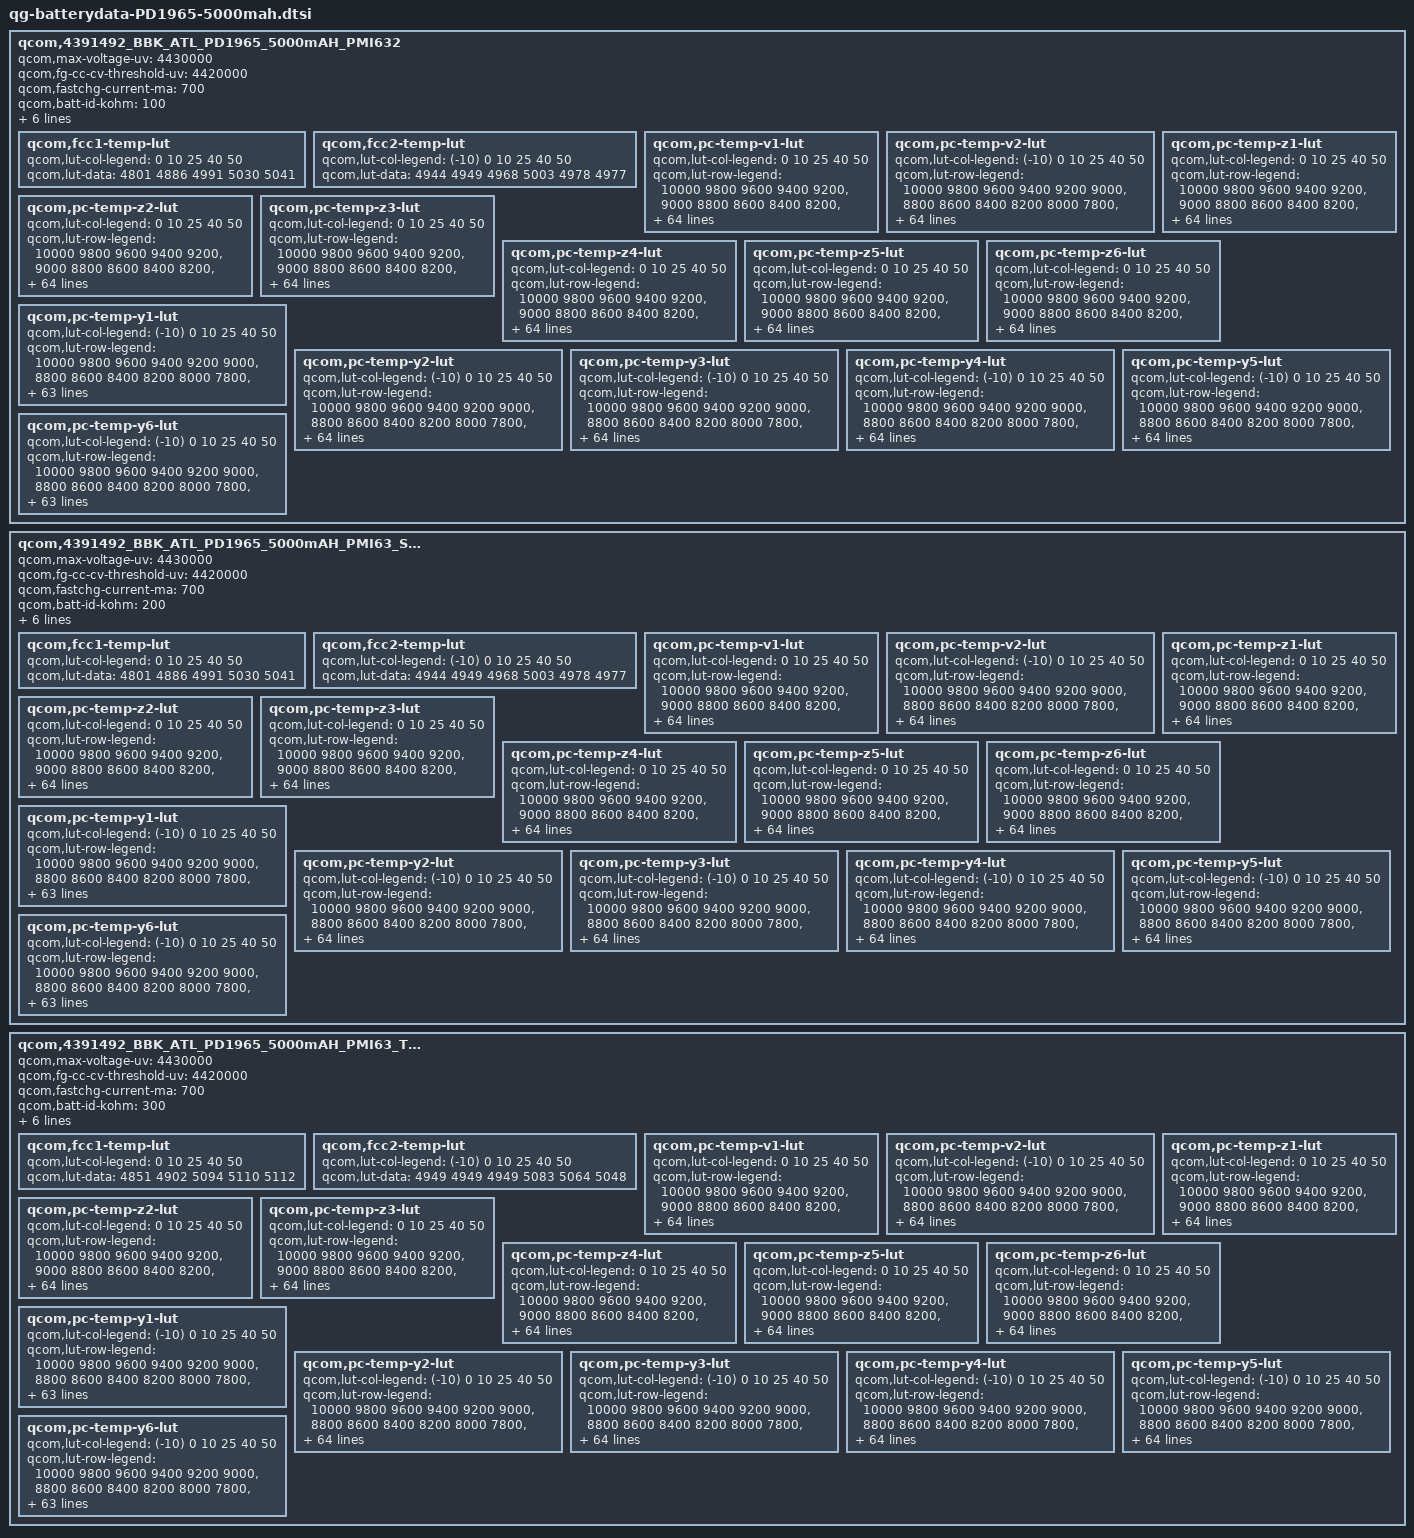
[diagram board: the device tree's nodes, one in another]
qcom,4391492_BBK_ATL_PD1965_5000mAH_PMI632 {
    /* 4391492_BBK_ATL_PD1965_5000mAH_PMI632_averaged_MasterSlave_Jan2th2020 */
    qcom,max-voltage-uv = <4430000>;
    qcom,fg-cc-cv-threshold-uv = <4420000>;
    qcom,fastchg-current-ma = <700>;
    qcom,batt-id-kohm = <100>;
    qcom,nom-batt-capacity-mah = <4880>;/*min value*/
    qcom,battery-beta = <3440>;
    qcom,battery-therm-kohm = <10>;
    qcom,battery-type = "4391492_BBK_ATL_PD1965_5000mAH_PMI632_averaged_MasterSlave_Jan2th2020";
    qcom,qg-batt-profile-ver = <100>;

	qcom,fcc1-temp-lut {
		qcom,lut-col-legend = <0 10 25 40 50>;
		qcom,lut-data = <4801 4886 4991 5030 5041>;
	};

	qcom,fcc2-temp-lut {
		qcom,lut-col-legend = <(-10) 0 10 25 40 50>;
		qcom,lut-data = <4944 4949 4968 5003 4978 4977>;
	};

	qcom,pc-temp-v1-lut {
		qcom,lut-col-legend = <0 10 25 40 50>;
		qcom,lut-row-legend = <10000 9800 9600 9400 9200>,
			<9000 8800 8600 8400 8200>,
			<8000 7800 7600 7400 7200>,
			<7000 6800 6600 6400 6200>,
			<6000 5800 5600 5400 5200>,
			<5000 4800 4600 4400 4200>,
			<4000 3800 3600 3400 3200>,
			<3000 2800 2600 2400 2200>,
			<2000 1800 1600 1400 1200>,
			<1000 900 800 700 600>,
			<500 400 300 200 100>,
			<0>;
		qcom,lut-data = <44061 44137 44195 44220 44225>,
			<43896 43960 44010 44027 44033>,
			<43679 43763 43816 43839 43847>,
			<43447 43549 43614 43642 43653>,
			<43217 43327 43400 43431 43447>,
			<42980 43094 43178 43212 43231>,
			<42744 42856 42942 42983 43006>,
			<42505 42617 42700 42747 42770>,
			<42269 42378 42459 42508 42533>,
			<42038 42140 42218 42266 42293>,
			<41811 41906 41979 42024 42052>,
			<41590 41675 41742 41787 41815>,
			<41372 41451 41509 41553 41581>,
			<41161 41235 41284 41323 41352>,
			<40958 41023 41065 41099 41129>,
			<40764 40817 40854 40882 40912>,
			<40574 40617 40648 40674 40702>,
			<40386 40427 40449 40474 40498>,
			<40200 40257 40265 40284 40304>,
			<40005 40080 40095 40109 40126>,
			<39791 39852 39909 39929 39945>,
			<39579 39578 39667 39704 39726>,
			<39384 39352 39415 39455 39481>,
			<39195 39187 39218 39246 39272>,
			<39039 39048 39057 39074 39097>,
			<38925 38925 38916 38924 38944>,
			<38829 38816 38792 38797 38811>,
			<38742 38719 38683 38686 38693>,
			<38661 38630 38584 38583 38584>,
			<38589 38549 38493 38484 38482>,
			<38526 38479 38412 38394 38388>,
			<38470 38415 38337 38310 38301>,
			<38419 38359 38270 38234 38221>,
			<38373 38308 38213 38167 38149>,
			<38330 38263 38167 38111 38086>,
			<38293 38219 38120 38055 38021>,
			<38260 38182 38072 37992 37944>,
			<38217 38138 38020 37924 37857>,
			<38138 38063 37948 37845 37767>,
			<38027 37952 37847 37750 37671>,
			<37903 37828 37733 37642 37564>,
			<37758 37687 37608 37516 37436>,
			<37610 37532 37467 37374 37293>,
			<37462 37353 37295 37212 37130>,
			<37305 37212 37154 37083 37014>,
			<37205 37125 37081 37014 36951>,
			<37170 37099 37059 36995 36933>,
			<37142 37079 37039 36982 36918>,
			<37109 37057 37014 36958 36891>,
			<37015 36951 36890 36798 36701>,
			<36674 36585 36528 36432 36331>,
			<36193 36111 36051 35952 35852>,
			<35580 35489 35438 35337 35235>,
			<34742 34642 34603 34498 34396>,
			<33413 33295 33303 33195 33092>,
			<30000 30000 30000 30000 30000>;
	};

	qcom,pc-temp-v2-lut {
		qcom,lut-col-legend = <(-10) 0 10 25 40 50>;
		qcom,lut-row-legend = <10000 9800 9600 9400 9200 9000>,
			<8800 8600 8400 8200 8000 7800>,
			<7600 7400 7200 7000 6800 6600>,
			<6400 6200 6000 5800 5600 5400>,
			<5200 5000 4800 4600 4400 4200>,
			<4000 3800 3600 3400 3200 3000>,
			<2800 2600 2400 2200 2000 1800>,
			<1600 1400 1200 1000 900 800>,
			<700 600 500 400 300 200>,
			<100 0>;
		qcom,lut-data = <44225 44175 44175 44190 44110 44115>,
			<43838 43904 43937 43970 43898 43903>,
			<43495 43643 43705 43752 43685 43689>,
			<43207 43396 43481 43536 43470 43476>,
			<42966 43163 43266 43323 43256 43263>,
			<42730 42928 43047 43104 43035 43044>,
			<42478 42681 42813 42871 42803 42814>,
			<42215 42431 42573 42630 42565 42576>,
			<41919 42185 42335 42390 42326 42339>,
			<41550 41945 42097 42146 42085 42099>,
			<41263 41709 41862 41906 41848 41863>,
			<41143 41470 41628 41668 41613 41629>,
			<41062 41236 41399 41435 41383 41399>,
			<40902 41023 41175 41207 41158 41174>,
			<40518 40835 40957 40983 40937 40953>,
			<40121 40642 40744 40766 40724 40740>,
			<39889 40420 40539 40557 40519 40533>,
			<39705 40177 40335 40354 40321 40333>,
			<39488 39932 40121 40159 40130 40142>,
			<39212 39677 39893 39974 39951 39964>,
			<38947 39429 39659 39773 39758 39773>,
			<38733 39198 39415 39519 39511 39528>,
			<38548 38981 39170 39253 39243 39263>,
			<38415 38794 38971 39051 39041 39061>,
			<38323 38635 38812 38889 38888 38907>,
			<38250 38492 38673 38749 38755 38774>,
			<38189 38356 38545 38623 38632 38650>,
			<38138 38228 38430 38511 38522 38538>,
			<38087 38129 38323 38406 38419 38434>,
			<38037 38055 38221 38307 38323 38335>,
			<37986 37993 38127 38217 38234 38245>,
			<37935 37940 38042 38134 38156 38163>,
			<37882 37893 37963 38057 38083 38086>,
			<37825 37845 37895 37982 38007 38003>,
			<37764 37798 37839 37910 37929 37914>,
			<37698 37748 37785 37835 37844 37817>,
			<37628 37688 37731 37753 37743 37703>,
			<37553 37620 37677 37667 37630 37578>,
			<37471 37539 37610 37583 37529 37469>,
			<37379 37442 37523 37501 37442 37380>,
			<37278 37330 37417 37409 37350 37287>,
			<37163 37201 37291 37295 37233 37167>,
			<37030 37051 37143 37164 37100 37031>,
			<36905 36898 36987 36993 36951 36888>,
			<36790 36757 36865 36914 36871 36810>,
			<36703 36665 36807 36886 36848 36787>,
			<36663 36626 36777 36869 36829 36768>,
			<36619 36577 36729 36840 36800 36740>,
			<36552 36490 36653 36783 36728 36646>,
			<36437 36316 36465 36614 36486 36366>,
			<36149 35975 36069 36201 36045 35916>,
			<35648 35477 35504 35666 35485 35348>,
			<34957 34800 34782 34970 34754 34598>,
			<33964 33826 33786 34010 33704 33557>,
			<32369 32283 32339 32559 32419 32087>,
			<29589 29119 29003 29070 29002 29003>;
	};

	qcom,pc-temp-z1-lut {
		qcom,lut-col-legend = <0 10 25 40 50>;
		qcom,lut-row-legend = <10000 9800 9600 9400 9200>,
			<9000 8800 8600 8400 8200>,
			<8000 7800 7600 7400 7200>,
			<7000 6800 6600 6400 6200>,
			<6000 5800 5600 5400 5200>,
			<5000 4800 4600 4400 4200>,
			<4000 3800 3600 3400 3200>,
			<3000 2800 2600 2400 2200>,
			<2000 1800 1600 1400 1200>,
			<1000 900 800 700 600>,
			<500 400 300 200 100>,
			<0>;
		qcom,lut-data = <12152 11640 11121 10911 10832>,
			<12122 11562 11036 10812 10751>,
			<12087 11520 10979 10773 10727>,
			<12059 11491 10965 10762 10720>,
			<12039 11480 10958 10759 10719>,
			<12017 11483 10953 10757 10717>,
			<12010 11488 10948 10753 10715>,
			<12010 11487 10944 10750 10713>,
			<12010 11472 10939 10747 10711>,
			<12009 11459 10934 10744 10710>,
			<12003 11460 10930 10742 10710>,
			<12000 11463 10926 10741 10709>,
			<12001 11463 10924 10741 10709>,
			<12001 11459 10923 10741 10709>,
			<12001 11455 10924 10742 10708>,
			<11996 11455 10925 10742 10707>,
			<11991 11456 10923 10741 10708>,
			<11991 11456 10921 10740 10710>,
			<11991 11450 10922 10739 10712>,
			<11993 11445 10926 10741 10712>,
			<12001 11449 10929 10742 10713>,
			<12010 11463 10931 10743 10713>,
			<12011 11469 10933 10744 10715>,
			<12003 11465 10936 10745 10716>,
			<12000 11460 10940 10748 10717>,
			<12013 11460 10944 10750 10718>,
			<12030 11463 10946 10753 10720>,
			<12033 11467 10948 10756 10723>,
			<12027 11469 10952 10759 10725>,
			<12022 11472 10958 10761 10727>,
			<12029 11473 10963 10764 10729>,
			<12046 11474 10966 10767 10732>,
			<12053 11475 10968 10771 10734>,
			<12042 11474 10971 10773 10737>,
			<12029 11474 10977 10775 10739>,
			<12030 11475 10982 10777 10741>,
			<12042 11483 10988 10781 10743>,
			<12051 11491 10994 10786 10746>,
			<12052 11495 10997 10788 10747>,
			<12052 11497 10999 10789 10749>,
			<12056 11500 11001 10789 10751>,
			<12074 11501 11002 10790 10753>,
			<12080 11504 11003 10792 10755>,
			<12076 11507 11005 10793 10755>,
			<12070 11519 11008 10794 10755>,
			<12063 11504 11011 10796 10753>,
			<12067 11500 11014 10797 10757>,
			<12065 11501 11016 10801 10755>,
			<12079 11501 11017 10801 10758>,
			<12078 11508 11019 10805 10761>,
			<12084 11524 11024 10808 10762>,
			<12106 11534 11030 10810 10766>,
			<12112 11537 11039 10818 10771>,
			<12156 11578 11050 10824 10776>,
			<12156 11578 11050 10824 10776>,
			<12156 11578 11050 10824 10776>;
	};

	qcom,pc-temp-z2-lut {
		qcom,lut-col-legend = <0 10 25 40 50>;
		qcom,lut-row-legend = <10000 9800 9600 9400 9200>,
			<9000 8800 8600 8400 8200>,
			<8000 7800 7600 7400 7200>,
			<7000 6800 6600 6400 6200>,
			<6000 5800 5600 5400 5200>,
			<5000 4800 4600 4400 4200>,
			<4000 3800 3600 3400 3200>,
			<3000 2800 2600 2400 2200>,
			<2000 1800 1600 1400 1200>,
			<1000 900 800 700 600>,
			<500 400 300 200 100>,
			<0>;
		qcom,lut-data = <11316 10650 11293 11777 11181>,
			<10578 10735 11148 11036 11105>,
			<10543 10721 11049 11125 11113>,
			<10542 10695 11020 11162 11126>,
			<10542 10684 11008 11157 11158>,
			<10543 10694 11002 11146 11195>,
			<10545 10711 11012 11109 11207>,
			<10553 10717 11029 11034 11203>,
			<10562 10720 11032 11011 11204>,
			<10565 10722 11036 11112 11229>,
			<10566 10728 11035 11212 11256>,
			<10567 10735 11027 11179 11246>,
			<10573 10737 11020 11081 11206>,
			<10581 10736 11024 11047 11189>,
			<10581 10736 11045 11071 11218>,
			<10572 10731 11057 11103 11253>,
			<10563 10718 11043 11128 11264>,
			<10559 10709 11023 11150 11275>,
			<10557 10703 11019 11154 11270>,
			<10550 10699 11018 11134 11245>,
			<10497 10695 11018 11116 11211>,
			<10441 10683 11015 11114 11168>,
			<10442 10671 11008 11109 11109>,
			<10467 10650 10996 11103 11075>,
			<10482 10630 10965 11092 11057>,
			<10474 10626 10948 11080 11047>,
			<10461 10627 10952 11065 11054>,
			<10458 10628 10958 11044 11077>,
			<10463 10636 10958 11039 11104>,
			<10470 10648 10950 11039 11142>,
			<10479 10654 10945 11050 11180>,
			<10491 10656 10974 11088 11218>,
			<10498 10658 11022 11137 11270>,
			<10501 10661 11049 11160 11306>,
			<10504 10664 11067 11139 11328>,
			<10509 10665 11082 11135 11353>,
			<10517 10669 11099 11220 11445>,
			<10526 10676 11121 11347 11583>,
			<10547 10704 11159 11404 11619>,
			<10572 10759 11234 11409 11570>,
			<10576 10779 11276 11397 11529>,
			<10560 10770 11237 11349 11467>,
			<10579 10766 11198 11296 11390>,
			<10784 10792 11224 11289 11356>,
			<11474 10833 11233 11304 11382>,
			<11833 10789 11240 11296 11320>,
			<11508 10793 11214 11209 11379>,
			<11152 10830 11172 11304 11450>,
			<11789 11061 11135 11310 11483>,
			<10999 10982 11277 11206 11127>,
			<10491 10912 11162 11075 11000>,
			<10250 10799 11088 10969 10908>,
			<9946 10805 11051 10910 10902>,
			<9604 10533 10977 10881 10801>,
			<9604 10533 10977 10881 10801>,
			<9604 10533 10977 10881 10801>;
	};

	qcom,pc-temp-z3-lut {
		qcom,lut-col-legend = <0 10 25 40 50>;
		qcom,lut-row-legend = <10000 9800 9600 9400 9200>,
			<9000 8800 8600 8400 8200>,
			<8000 7800 7600 7400 7200>,
			<7000 6800 6600 6400 6200>,
			<6000 5800 5600 5400 5200>,
			<5000 4800 4600 4400 4200>,
			<4000 3800 3600 3400 3200>,
			<3000 2800 2600 2400 2200>,
			<2000 1800 1600 1400 1200>,
			<1000 900 800 700 600>,
			<500 400 300 200 100>,
			<0>;
		qcom,lut-data = <19258 19323 19328 19307 19299>,
			<19291 19439 19376 19327 19315>,
			<19488 19498 19406 19338 19319>,
			<19653 19537 19408 19343 19320>,
			<19674 19552 19402 19343 19320>,
			<19685 19547 19398 19343 19320>,
			<19687 19538 19396 19340 19320>,
			<19679 19529 19394 19332 19319>,
			<19667 19519 19390 19328 19318>,
			<19659 19513 19379 19327 19318>,
			<19652 19513 19374 19327 19319>,
			<19647 19513 19375 19327 19318>,
			<19641 19512 19376 19327 19317>,
			<19636 19503 19373 19327 19315>,
			<19635 19496 19359 19325 19311>,
			<19639 19499 19351 19322 19307>,
			<19642 19507 19353 19319 19306>,
			<19642 19510 19355 19314 19305>,
			<19642 19502 19355 19312 19304>,
			<19643 19495 19356 19312 19302>,
			<19660 19500 19358 19314 19301>,
			<19680 19521 19376 19324 19306>,
			<19687 19537 19399 19345 19321>,
			<19692 19547 19404 19353 19327>,
			<19695 19553 19404 19354 19328>,
			<19697 19552 19404 19355 19329>,
			<19699 19547 19405 19349 19328>,
			<19698 19542 19405 19336 19326>,
			<19691 19537 19403 19331 19325>,
			<19682 19533 19395 19330 19325>,
			<19674 19527 19389 19330 19324>,
			<19666 19521 19388 19330 19323>,
			<19661 19515 19387 19331 19320>,
			<19657 19511 19385 19331 19317>,
			<19654 19508 19379 19329 19314>,
			<19652 19506 19376 19326 19312>,
			<19649 19506 19377 19325 19312>,
			<19646 19506 19379 19324 19313>,
			<19638 19500 19379 19324 19314>,
			<19628 19489 19375 19322 19314>,
			<19624 19484 19371 19322 19315>,
			<19624 19487 19367 19325 19315>,
			<19582 19488 19364 19328 19317>,
			<19282 19476 19365 19327 19321>,
			<19259 19451 19364 19324 19315>,
			<19258 19450 19348 19320 19307>,
			<19258 19447 19349 19321 19305>,
			<19258 19433 19351 19313 19303>,
			<19258 19348 19347 19306 19300>,
			<19258 19379 19344 19323 19318>,
			<19259 19408 19356 19327 19321>,
			<19260 19288 19358 19332 19322>,
			<19262 19314 19352 19329 19326>,
			<19266 19311 19341 19334 19328>,
			<19266 19311 19341 19334 19328>,
			<19266 19311 19341 19334 19328>;
	};

	qcom,pc-temp-z4-lut {
		qcom,lut-col-legend = <0 10 25 40 50>;
		qcom,lut-row-legend = <10000 9800 9600 9400 9200>,
			<9000 8800 8600 8400 8200>,
			<8000 7800 7600 7400 7200>,
			<7000 6800 6600 6400 6200>,
			<6000 5800 5600 5400 5200>,
			<5000 4800 4600 4400 4200>,
			<4000 3800 3600 3400 3200>,
			<3000 2800 2600 2400 2200>,
			<2000 1800 1600 1400 1200>,
			<1000 900 800 700 600>,
			<500 400 300 200 100>,
			<0>;
		qcom,lut-data = <15453 15196 14961 14781 14759>,
			<15468 15215 14956 14833 14781>,
			<15391 15195 14945 14808 14764>,
			<15294 15105 14926 14791 14751>,
			<15193 15027 14887 14782 14745>,
			<15085 14988 14856 14775 14741>,
			<15031 14958 14841 14769 14736>,
			<15011 14939 14830 14765 14732>,
			<14997 14927 14821 14760 14727>,
			<14983 14916 14814 14753 14721>,
			<14969 14901 14806 14746 14715>,
			<14960 14885 14794 14739 14711>,
			<14954 14876 14782 14732 14707>,
			<14949 14869 14777 14726 14703>,
			<14948 14866 14775 14720 14699>,
			<14948 14869 14773 14715 14695>,
			<14948 14875 14766 14709 14690>,
			<14950 14877 14758 14704 14683>,
			<14958 14866 14754 14700 14679>,
			<14972 14853 14751 14696 14677>,
			<15025 14904 14751 14694 14676>,
			<15087 15063 14804 14714 14689>,
			<15120 15140 14881 14759 14723>,
			<15154 15092 14891 14773 14737>,
			<15170 15021 14876 14772 14738>,
			<15131 14984 14859 14771 14738>,
			<15065 14960 14842 14768 14736>,
			<15036 14945 14826 14765 14730>,
			<15023 14935 14817 14760 14724>,
			<15016 14928 14810 14751 14717>,
			<15014 14924 14805 14742 14710>,
			<15012 14922 14800 14733 14705>,
			<15011 14921 14796 14726 14700>,
			<15010 14919 14792 14722 14696>,
			<15009 14918 14788 14719 14693>,
			<15005 14916 14786 14718 14691>,
			<14996 14911 14793 14728 14697>,
			<14987 14905 14805 14747 14711>,
			<14980 14900 14807 14751 14714>,
			<14973 14895 14807 14745 14710>,
			<14961 14887 14806 14737 14705>,
			<14939 14869 14793 14729 14701>,
			<14965 14855 14780 14723 14698>,
			<15203 14850 14779 14726 14703>,
			<15177 14825 14771 14725 14703>,
			<15146 14784 14752 14714 14691>,
			<15137 14766 14729 14701 14679>,
			<15126 14763 14705 14683 14663>,
			<15115 14839 14695 14679 14658>,
			<15115 14813 14715 14682 14663>,
			<15136 14797 14705 14679 14662>,
			<15144 14920 14701 14674 14662>,
			<15151 14897 14707 14676 14659>,
			<15181 14909 14717 14673 14659>,
			<15181 14909 14717 14673 14659>,
			<15181 14909 14717 14673 14659>;
	};

	qcom,pc-temp-z5-lut {
		qcom,lut-col-legend = <0 10 25 40 50>;
		qcom,lut-row-legend = <10000 9800 9600 9400 9200>,
			<9000 8800 8600 8400 8200>,
			<8000 7800 7600 7400 7200>,
			<7000 6800 6600 6400 6200>,
			<6000 5800 5600 5400 5200>,
			<5000 4800 4600 4400 4200>,
			<4000 3800 3600 3400 3200>,
			<3000 2800 2600 2400 2200>,
			<2000 1800 1600 1400 1200>,
			<1000 900 800 700 600>,
			<500 400 300 200 100>,
			<0>;
		qcom,lut-data = <11158 12046 13940 14471 15125>,
			<11606 14259 16208 16833 17677>,
			<13986 16162 17732 17960 18263>,
			<16501 17974 18122 18545 18557>,
			<18058 18936 18261 18831 18767>,
			<19333 19189 18360 18990 18904>,
			<19700 19332 18472 18672 18957>,
			<19583 19284 18558 17741 18921>,
			<19428 18919 18408 17324 18920>,
			<19333 18663 17717 17467 19171>,
			<19240 18914 17321 17644 19460>,
			<19194 19378 17666 17759 19500>,
			<19112 19474 18146 18047 19457>,
			<19019 19128 17971 18160 19382>,
			<19144 18814 16869 18180 18826>,
			<19663 19161 16228 18178 18225>,
			<20061 20028 16501 17923 18195>,
			<19866 20331 16930 17359 18323>,
			<19399 19818 17206 17139 18396>,
			<19319 19222 17681 17429 18363>,
			<21137 19107 17901 17728 18248>,
			<23141 19215 17668 17686 17948>,
			<22748 19288 17346 17573 17457>,
			<20514 19219 17200 17602 17242>,
			<19211 19165 17184 17711 17187>,
			<19788 19411 17310 17778 17160>,
			<20863 20291 18077 17452 17313>,
			<21650 21201 19141 16765 17734>,
			<22341 22012 19567 16600 18102>,
			<22777 22724 19675 16978 19032>,
			<22859 22962 19910 17581 19849>,
			<22899 23042 20865 18552 20166>,
			<22938 23101 22060 19846 20721>,
			<22988 23156 22509 20636 21279>,
			<23029 23206 22547 21269 21955>,
			<23043 23303 22561 21610 22371>,
			<23030 23577 22883 21099 21798>,
			<23023 23798 23285 20129 20634>,
			<23024 23535 23227 19785 20348>,
			<23000 22858 22500 19417 20713>,
			<22928 22616 21665 19274 21070>,
			<22801 23027 20882 19855 21409>,
			<21309 23190 20236 20406 21801>,
			<12195 21264 19817 19776 22252>,
			<11411 19246 19595 18776 20258>,
			<11333 19812 18166 18422 18025>,
			<11317 19801 19192 19856 18766>,
			<11291 18707 21166 19869 20950>,
			<11233 13373 21303 19330 21183>,
			<11246 15041 17862 19535 22967>,
			<11268 15831 18956 19538 22898>,
			<11213 11840 18776 20570 22999>,
			<11137 12141 17447 19547 24357>,
			<11084 11961 16052 20015 23848>,
			<11084 11961 16052 20015 23848>,
			<11084 11961 16052 20015 23848>;
	};

	qcom,pc-temp-z6-lut {
		qcom,lut-col-legend = <0 10 25 40 50>;
		qcom,lut-row-legend = <10000 9800 9600 9400 9200>,
			<9000 8800 8600 8400 8200>,
			<8000 7800 7600 7400 7200>,
			<7000 6800 6600 6400 6200>,
			<6000 5800 5600 5400 5200>,
			<5000 4800 4600 4400 4200>,
			<4000 3800 3600 3400 3200>,
			<3000 2800 2600 2400 2200>,
			<2000 1800 1600 1400 1200>,
			<1000 900 800 700 600>,
			<500 400 300 200 100>,
			<0>;
		qcom,lut-data = <15443 14980 14630 14494 14470>,
			<15409 15014 14637 14510 14468>,
			<15404 15009 14636 14499 14459>,
			<15398 14969 14626 14491 14454>,
			<15357 14929 14604 14487 14452>,
			<15276 14901 14586 14483 14450>,
			<15224 14877 14577 14478 14447>,
			<15200 14858 14570 14472 14444>,
			<15181 14843 14562 14467 14441>,
			<15165 14830 14553 14463 14439>,
			<15150 14820 14545 14459 14436>,
			<15139 14811 14540 14456 14434>,
			<15129 14802 14536 14453 14431>,
			<15122 14792 14530 14450 14429>,
			<15120 14786 14523 14447 14425>,
			<15120 14788 14517 14443 14421>,
			<15120 14793 14514 14439 14418>,
			<15121 14794 14512 14434 14415>,
			<15125 14785 14512 14432 14413>,
			<15133 14776 14511 14431 14412>,
			<15165 14802 14512 14430 14410>,
			<15204 14885 14545 14444 14419>,
			<15228 14925 14592 14476 14443>,
			<15251 14910 14598 14487 14453>,
			<15262 14886 14593 14487 14454>,
			<15249 14872 14587 14487 14454>,
			<15227 14861 14581 14484 14453>,
			<15216 14854 14575 14476 14449>,
			<15211 14850 14570 14470 14446>,
			<15208 14846 14563 14466 14443>,
			<15206 14844 14559 14462 14440>,
			<15206 14841 14558 14460 14437>,
			<15206 14840 14557 14458 14434>,
			<15208 14840 14555 14456 14431>,
			<15210 14840 14552 14453 14428>,
			<15212 14841 14550 14452 14426>,
			<15215 14843 14555 14456 14430>,
			<15216 14845 14562 14465 14436>,
			<15217 14844 14564 14466 14438>,
			<15219 14841 14563 14463 14437>,
			<15220 14839 14561 14460 14435>,
			<15223 14838 14554 14459 14434>,
			<15221 14836 14548 14458 14434>,
			<15191 14834 14549 14459 14438>,
			<15183 14819 14547 14458 14436>,
			<15181 14805 14532 14450 14426>,
			<15180 14799 14522 14445 14420>,
			<15181 14793 14514 14434 14412>,
			<15182 14786 14508 14429 14409>,
			<15196 14799 14518 14440 14421>,
			<15218 14813 14521 14441 14423>,
			<15233 14812 14523 14443 14424>,
			<15255 14826 14525 14444 14427>,
			<15297 14844 14528 14447 14429>,
			<15297 14844 14528 14447 14429>,
			<15297 14844 14528 14447 14429>;
	};

	qcom,pc-temp-y1-lut {
		qcom,lut-col-legend = <(-10) 0 10 25 40 50>;
		qcom,lut-row-legend = <10000 9800 9600 9400 9200 9000>,
			<8800 8600 8400 8200 8000 7800>,
			<7600 7400 7200 7000 6800 6600>,
			<6400 6200 6000 5800 5600 5400>,
			<5200 5000 4800 4600 4400 4200>,
			<4000 3800 3600 3400 3200 3000>,
			<2800 2600 2400 2200 2000 1800>,
			<1600 1400 1200 1000 900 800>,
			<700 600 500 400 300 200>,
			<100 0>;
		qcom,lut-data = <5866 5422 5158 4850 4705 4669>,
			<5876 5418 5147 4841 4702 4668>,
			<5881 5413 5134 4832 4698 4668>,
			<5884 5407 5121 4823 4694 4667>,
			<5885 5402 5111 4816 4691 4667>,
			<5886 5400 5106 4810 4688 4666>,
			<5878 5400 5106 4807 4687 4665>,
			<5866 5401 5108 4804 4685 4663>,
			<5865 5401 5106 4800 4684 4662>,
			<5881 5401 5101 4796 4683 4661>,
			<5893 5401 5096 4792 4683 4660>,
			<5888 5403 5093 4789 4681 4660>,
			<5877 5406 5090 4786 4678 4659>,
			<5874 5407 5090 4786 4676 4660>,
			<5874 5402 5091 4788 4675 4661>,
			<5874 5398 5093 4789 4675 4662>,
			<5877 5399 5093 4791 4676 4662>,
			<5884 5402 5092 4792 4679 4661>,
			<5886 5403 5093 4793 4680 4661>,
			<5881 5402 5094 4795 4681 4662>,
			<5877 5402 5096 4796 4682 4662>,
			<5878 5403 5097 4797 4682 4663>,
			<5879 5406 5099 4799 4682 4664>,
			<5882 5409 5101 4801 4683 4664>,
			<5901 5411 5104 4802 4683 4664>,
			<5921 5413 5106 4804 4684 4665>,
			<5921 5415 5107 4805 4685 4666>,
			<5918 5417 5107 4807 4687 4668>,
			<5913 5418 5108 4808 4688 4669>,
			<5897 5414 5105 4810 4689 4669>,
			<5882 5409 5102 4812 4690 4670>,
			<5886 5409 5105 4814 4692 4671>,
			<5902 5410 5113 4817 4695 4672>,
			<5909 5411 5115 4819 4697 4673>,
			<5896 5415 5113 4823 4701 4674>,
			<5880 5419 5111 4826 4704 4675>,
			<5880 5418 5112 4827 4706 4676>,
			<5886 5414 5114 4828 4708 4679>,
			<5890 5412 5115 4830 4708 4680>,
			<5889 5413 5115 4833 4709 4681>,
			<5888 5414 5115 4836 4710 4682>,
			<5884 5415 5121 4837 4713 4683>,
			<5876 5416 5134 4838 4716 4685>,
			<5875 5420 5132 4838 4716 4685>,
			<5880 5427 5131 4843 4716 4685>,
			<5891 5426 5144 4846 4718 4688>,
			<5890 5435 5141 4852 4718 4689>,
			<5890 5446 5134 4853 4721 4689>,
			<5928 5436 5136 4855 4721 4688>,
			<5898 5452 5140 4851 4720 4689>,
			<5901 5462 5143 4857 4721 4691>,
			<5936 5486 5147 4862 4725 4692>,
			<5968 5480 5163 4867 4729 4695>,
			<5880 5483 5180 4875 4735 4701>,
			<5880 5483 5180 4875 4735 4701>,
			<5880 5483 5180 4875 4735 4701>;
	};

	qcom,pc-temp-y2-lut {
		qcom,lut-col-legend = <(-10) 0 10 25 40 50>;
		qcom,lut-row-legend = <10000 9800 9600 9400 9200 9000>,
			<8800 8600 8400 8200 8000 7800>,
			<7600 7400 7200 7000 6800 6600>,
			<6400 6200 6000 5800 5600 5400>,
			<5200 5000 4800 4600 4400 4200>,
			<4000 3800 3600 3400 3200 3000>,
			<2800 2600 2400 2200 2000 1800>,
			<1600 1400 1200 1000 900 800>,
			<700 600 500 400 300 200>,
			<100 0>;
		qcom,lut-data = <9643 10863 11325 11833 11821 12383>,
			<9643 10886 11297 11772 11792 12238>,
			<9643 10907 11271 11699 11763 12078>,
			<9788 10924 11246 11627 11736 11926>,
			<10004 10936 11223 11570 11711 11804>,
			<10107 10940 11203 11542 11690 11733>,
			<10237 10936 11182 11542 11672 11710>,
			<10446 10929 11165 11547 11655 11704>,
			<10426 10925 11164 11537 11633 11702>,
			<10015 10923 11179 11514 11599 11688>,
			<9700 10924 11191 11501 11570 11678>,
			<9926 10932 11192 11532 11554 11655>,
			<10380 10948 11191 11578 11552 11614>,
			<10465 10982 11194 11586 11576 11601>,
			<10054 11088 11209 11580 11657 11598>,
			<9700 11170 11234 11573 11711 11596>,
			<9684 11164 11291 11569 11696 11628>,
			<9682 11143 11368 11572 11669 11684>,
			<9679 11126 11385 11603 11679 11693>,
			<9674 11101 11360 11698 11789 11656>,
			<9670 11083 11340 11760 11887 11628>,
			<9667 11093 11348 11767 11914 11718>,
			<9666 11121 11371 11771 11926 11901>,
			<9664 11142 11398 11772 11929 12000>,
			<9663 11155 11442 11779 11934 12079>,
			<9661 11163 11482 11785 11946 12128>,
			<9660 11088 11498 11783 11982 12129>,
			<9659 10845 11510 11779 12032 12125>,
			<9658 10593 11518 11791 12046 12130>,
			<9658 10291 11531 11848 12064 12167>,
			<9657 10028 11536 11887 12092 12208>,
			<9657 9923 11522 11881 12148 12281>,
			<9656 9862 11496 11865 12228 12394>,
			<9656 9812 11478 11858 12247 12417>,
			<9655 9764 11470 11854 12221 12338>,
			<9655 9725 11460 11857 12184 12263>,
			<9655 9704 11433 11905 12128 12276>,
			<9655 9689 11376 11967 12052 12330>,
			<9655 9680 11310 11968 12016 12331>,
			<9655 9673 11234 11923 12007 12236>,
			<9655 9668 11141 11889 12008 12143>,
			<9655 9664 11029 11897 12026 12059>,
			<9654 9661 10892 11912 12043 11954>,
			<9654 9659 10728 11841 11957 12038>,
			<9654 9658 10565 11738 11850 12125>,
			<9654 9656 10476 11679 11873 12005>,
			<9653 9656 10385 11758 11851 11882>,
			<9653 9655 10185 11740 11736 11687>,
			<9653 9655 10035 11593 11707 11618>,
			<9652 9654 9823 11562 11682 11685>,
			<9650 9653 9730 11449 11604 11615>,
			<9650 9652 9683 11385 11542 11492>,
			<9649 9651 9664 11218 11436 11359>,
			<9649 9655 9665 11146 11230 11183>,
			<9649 9655 9665 11146 11230 11183>,
			<9649 9655 9665 11146 11230 11183>;
	};

	qcom,pc-temp-y3-lut {
		qcom,lut-col-legend = <(-10) 0 10 25 40 50>;
		qcom,lut-row-legend = <10000 9800 9600 9400 9200 9000>,
			<8800 8600 8400 8200 8000 7800>,
			<7600 7400 7200 7000 6800 6600>,
			<6400 6200 6000 5800 5600 5400>,
			<5200 5000 4800 4600 4400 4200>,
			<4000 3800 3600 3400 3200 3000>,
			<2800 2600 2400 2200 2000 1800>,
			<1600 1400 1200 1000 900 800>,
			<700 600 500 400 300 200>,
			<100 0>;
		qcom,lut-data = <13657 13395 13321 13289 13273 13269>,
			<13659 13398 13322 13288 13272 13269>,
			<13655 13400 13325 13287 13272 13269>,
			<13648 13402 13328 13286 13272 13269>,
			<13639 13403 13330 13285 13272 13270>,
			<13629 13403 13331 13285 13272 13270>,
			<13617 13403 13332 13285 13273 13270>,
			<13601 13402 13332 13285 13275 13271>,
			<13580 13402 13332 13285 13275 13271>,
			<13546 13405 13333 13284 13275 13272>,
			<13521 13409 13334 13283 13274 13273>,
			<13517 13414 13335 13283 13274 13273>,
			<13515 13420 13335 13285 13274 13273>,
			<13515 13420 13336 13285 13274 13273>,
			<13527 13409 13337 13286 13274 13273>,
			<13540 13397 13337 13287 13275 13272>,
			<13548 13392 13337 13289 13276 13272>,
			<13555 13388 13335 13291 13278 13273>,
			<13555 13382 13333 13294 13280 13273>,
			<13536 13373 13329 13297 13283 13275>,
			<13514 13363 13325 13298 13285 13277>,
			<13506 13356 13320 13294 13281 13275>,
			<13501 13351 13315 13289 13274 13270>,
			<13500 13346 13312 13286 13272 13269>,
			<13529 13343 13309 13284 13272 13269>,
			<13575 13340 13308 13283 13272 13270>,
			<13623 13331 13308 13283 13272 13270>,
			<13682 13313 13308 13283 13271 13269>,
			<13745 13296 13307 13283 13271 13269>,
			<13811 13277 13305 13282 13271 13270>,
			<13885 13264 13303 13282 13271 13270>,
			<13972 13271 13304 13282 13272 13269>,
			<14074 13297 13305 13282 13273 13269>,
			<14182 13319 13306 13282 13274 13269>,
			<14295 13332 13305 13281 13273 13268>,
			<14413 13344 13305 13281 13273 13268>,
			<14535 13361 13306 13278 13272 13268>,
			<14663 13383 13307 13276 13271 13268>,
			<14783 13411 13309 13275 13271 13269>,
			<14893 13451 13310 13275 13271 13269>,
			<14997 13506 13312 13276 13271 13270>,
			<15094 13582 13316 13276 13271 13270>,
			<15184 13694 13322 13276 13271 13270>,
			<15280 13835 13329 13276 13271 13270>,
			<15390 14018 13340 13279 13272 13270>,
			<15548 14243 13354 13282 13272 13271>,
			<15624 14324 13356 13284 13274 13273>,
			<15813 14506 13366 13284 13276 13275>,
			<16086 14725 13388 13290 13280 13275>,
			<16533 15024 13414 13293 13278 13274>,
			<17955 15431 13458 13290 13277 13275>,
			<21143 16038 13556 13294 13278 13276>,
			<28534 17939 13794 13297 13280 13276>,
			<46189 22216 14569 13304 13283 13277>,
			<46189 22216 14569 13304 13283 13277>,
			<46189 22216 14569 13304 13283 13277>;
	};

	qcom,pc-temp-y4-lut {
		qcom,lut-col-legend = <(-10) 0 10 25 40 50>;
		qcom,lut-row-legend = <10000 9800 9600 9400 9200 9000>,
			<8800 8600 8400 8200 8000 7800>,
			<7600 7400 7200 7000 6800 6600>,
			<6400 6200 6000 5800 5600 5400>,
			<5200 5000 4800 4600 4400 4200>,
			<4000 3800 3600 3400 3200 3000>,
			<2800 2600 2400 2200 2000 1800>,
			<1600 1400 1200 1000 900 800>,
			<700 600 500 400 300 200>,
			<100 0>;
		qcom,lut-data = <17314 16785 16600 16501 16457 16446>,
			<17470 16872 16638 16500 16458 16446>,
			<17621 16974 16670 16499 16459 16447>,
			<17751 17071 16695 16499 16459 16447>,
			<17843 17145 16711 16499 16459 16447>,
			<17880 17176 16718 16499 16460 16448>,
			<17849 17165 16711 16500 16459 16448>,
			<17797 17142 16698 16501 16459 16447>,
			<17785 17122 16690 16504 16460 16448>,
			<17797 17104 16685 16510 16464 16448>,
			<17819 17087 16683 16516 16468 16449>,
			<17947 17069 16685 16521 16473 16452>,
			<18166 17051 16692 16526 16478 16456>,
			<18193 17063 16702 16532 16482 16460>,
			<17874 17202 16720 16540 16487 16465>,
			<17571 17319 16746 16550 16492 16471>,
			<17514 17301 16801 16562 16498 16476>,
			<17486 17241 16871 16578 16506 16482>,
			<17428 17171 16886 16604 16518 16492>,
			<17260 17080 16869 16650 16542 16508>,
			<17084 16981 16840 16675 16558 16518>,
			<16981 16888 16765 16626 16535 16503>,
			<16901 16797 16651 16546 16491 16471>,
			<16876 16737 16600 16513 16472 16458>,
			<16875 16696 16581 16497 16465 16454>,
			<16877 16671 16570 16490 16462 16452>,
			<16878 16665 16565 16491 16463 16453>,
			<16880 16662 16563 16493 16466 16455>,
			<16882 16663 16561 16496 16469 16457>,
			<16892 16695 16561 16502 16474 16460>,
			<16904 16728 16560 16509 16479 16465>,
			<16915 16727 16556 16517 16487 16472>,
			<16925 16714 16548 16524 16497 16480>,
			<16936 16709 16543 16525 16499 16481>,
			<16952 16728 16541 16525 16498 16477>,
			<16969 16757 16540 16524 16497 16470>,
			<16981 16776 16544 16509 16489 16464>,
			<16990 16793 16556 16488 16472 16457>,
			<17000 16806 16567 16482 16465 16455>,
			<17015 16820 16577 16480 16463 16454>,
			<17028 16833 16590 16480 16462 16454>,
			<17034 16838 16607 16482 16461 16452>,
			<17036 16845 16630 16483 16459 16450>,
			<17039 16866 16653 16479 16451 16441>,
			<17044 16925 16685 16481 16448 16438>,
			<17080 17034 16729 16498 16466 16450>,
			<17074 17043 16744 16509 16471 16455>,
			<17120 17153 16799 16525 16478 16482>,
			<17197 17268 16872 16541 16500 16486>,
			<17289 17390 16922 16547 16476 16455>,
			<17656 17464 16946 16518 16460 16450>,
			<18914 17560 17015 16540 16466 16461>,
			<25385 18839 17177 16582 16487 16479>,
			<65535 25835 17615 16666 16570 16587>,
			<65535 25835 17615 16666 16570 16587>,
			<65535 25835 17615 16666 16570 16587>;
	};

	qcom,pc-temp-y5-lut {
		qcom,lut-col-legend = <(-10) 0 10 25 40 50>;
		qcom,lut-row-legend = <10000 9800 9600 9400 9200 9000>,
			<8800 8600 8400 8200 8000 7800>,
			<7600 7400 7200 7000 6800 6600>,
			<6400 6200 6000 5800 5600 5400>,
			<5200 5000 4800 4600 4400 4200>,
			<4000 3800 3600 3400 3200 3000>,
			<2800 2600 2400 2200 2000 1800>,
			<1600 1400 1200 1000 900 800>,
			<700 600 500 400 300 200>,
			<100 0>;
		qcom,lut-data = <8712 15026 15531 19379 18638 18873>,
			<9360 15119 15904 18548 17744 18608>,
			<10576 15245 16140 17660 16983 18158>,
			<11994 15378 16270 16808 16379 17659>,
			<13263 15489 16325 16083 15956 17247>,
			<14035 15551 16337 15578 15737 17058>,
			<14489 15571 16219 15286 15817 17054>,
			<14915 15584 16000 15055 16004 17066>,
			<14736 15593 15886 14708 15871 17050>,
			<12904 15602 15821 14083 15297 17011>,
			<11479 15610 15739 13661 14730 16948>,
			<12549 15578 15515 13567 14342 16593>,
			<14696 15478 15153 13535 14012 15943>,
			<15204 15296 14819 13512 13842 15430>,
			<14206 14679 14439 13405 13754 14985>,
			<13348 14198 14220 13364 13731 14634>,
			<13770 14577 14233 13448 13885 14355>,
			<14768 15494 14280 13593 14218 14131>,
			<15057 16055 14480 13868 14600 14166>,
			<14465 16396 15586 14491 15325 14740>,
			<13590 16584 16549 15259 15825 15286>,
			<12641 16563 16736 16292 15795 15530>,
			<11562 16490 16839 17335 15685 15785>,
			<11068 16445 16846 17774 15792 16147>,
			<10902 16347 16717 17964 16568 17165>,
			<10820 16160 16608 18032 17165 17899>,
			<10865 15249 16733 18059 16986 17708>,
			<11010 13133 17019 18046 16558 17319>,
			<11098 11831 17109 17862 16231 17186>,
			<11103 11232 16758 17390 15906 17069>,
			<11101 10899 16449 17128 15714 16894>,
			<11141 10966 16849 17302 16092 16557>,
			<11213 11269 17719 17578 16970 16109>,
			<11261 11523 17992 17684 17585 16020>,
			<11243 11692 17704 17734 18052 16389>,
			<11210 11822 17336 17749 18308 16850>,
			<11241 11913 17101 17071 18178 17152>,
			<11311 12019 16893 16061 17864 17432>,
			<11345 12061 16680 15765 17701 17821>,
			<11305 11977 16193 15672 17545 18525>,
			<11235 11862 15697 15633 17323 19031>,
			<11172 11812 15469 15520 16906 18864>,
			<11091 11756 15327 15452 16491 18547>,
			<11065 11698 15309 15545 17844 20219>,
			<11049 11600 15301 16184 18667 20877>,
			<11033 11430 15185 16286 15912 17920>,
			<11063 11516 14855 16092 15975 19179>,
			<11193 11505 14142 15093 16646 19341>,
			<11223 11473 13900 16259 18048 18109>,
			<11359 11461 13490 17612 18268 20127>,
			<10615 11359 12967 17171 18333 22819>,
			<9756 11135 12259 17813 18591 21884>,
			<9138 9970 11638 17415 19016 19509>,
			<8857 9145 10890 17138 18770 18664>,
			<8857 9145 10890 17138 18770 18664>,
			<8857 9145 10890 17138 18770 18664>;
	};

	qcom,pc-temp-y6-lut {
		qcom,lut-col-legend = <(-10) 0 10 25 40 50>;
		qcom,lut-row-legend = <10000 9800 9600 9400 9200 9000>,
			<8800 8600 8400 8200 8000 7800>,
			<7600 7400 7200 7000 6800 6600>,
			<6400 6200 6000 5800 5600 5400>,
			<5200 5000 4800 4600 4400 4200>,
			<4000 3800 3600 3400 3200 3000>,
			<2800 2600 2400 2200 2000 1800>,
			<1600 1400 1200 1000 900 800>,
			<700 600 500 400 300 200>,
			<100 0>;
		qcom,lut-data = <6073 5498 5176 5004 4961 4950>,
			<6141 5510 5177 5003 4960 4950>,
			<6193 5518 5177 5000 4960 4950>,
			<6230 5522 5177 4998 4960 4951>,
			<6253 5523 5177 4996 4960 4951>,
			<6260 5523 5177 4995 4960 4951>,
			<6251 5515 5172 4995 4960 4952>,
			<6228 5497 5164 4995 4961 4952>,
			<6197 5485 5158 4995 4961 4953>,
			<6135 5475 5154 4995 4962 4953>,
			<6094 5468 5151 4996 4963 4954>,
			<6144 5461 5151 4997 4963 4955>,
			<6242 5456 5151 4999 4965 4956>,
			<6258 5458 5152 5001 4966 4957>,
			<6146 5485 5157 5004 4968 4959>,
			<6048 5509 5164 5008 4970 4960>,
			<6043 5502 5178 5012 4972 4962>,
			<6042 5483 5196 5019 4976 4963>,
			<6036 5459 5200 5028 4981 4966>,
			<5988 5428 5192 5043 4990 4973>,
			<5941 5394 5180 5051 4996 4977>,
			<5931 5365 5155 5035 4986 4971>,
			<5925 5338 5120 5008 4968 4959>,
			<5926 5324 5104 4997 4962 4954>,
			<5961 5317 5098 4991 4960 4953>,
			<6016 5313 5095 4989 4959 4952>,
			<6064 5308 5096 4990 4959 4952>,
			<6116 5304 5096 4991 4960 4953>,
			<6171 5303 5097 4992 4960 4954>,
			<6230 5310 5097 4993 4962 4955>,
			<6294 5324 5098 4995 4963 4956>,
			<6365 5339 5099 4997 4966 4958>,
			<6443 5360 5100 5000 4970 4960>,
			<6526 5386 5102 5000 4972 4960>,
			<6616 5418 5104 5000 4971 4959>,
			<6710 5458 5107 5000 4971 4957>,
			<6806 5503 5112 4995 4968 4955>,
			<6905 5557 5119 4988 4963 4954>,
			<6999 5617 5128 4986 4961 4953>,
			<7087 5686 5138 4986 4961 4954>,
			<7171 5765 5150 4987 4961 4954>,
			<7248 5854 5168 4988 4961 4954>,
			<7321 5958 5194 4989 4960 4953>,
			<7398 6090 5224 4989 4958 4951>,
			<7486 6260 5268 4991 4958 4951>,
			<7619 6476 5314 5000 4964 4955>,
			<7678 6544 5327 5006 4966 4958>,
			<7839 6715 5372 5012 4970 4967>,
			<8071 6924 5436 5020 4979 4968>,
			<8446 7190 5500 5024 4971 4959>,
			<9650 7528 5576 5014 4966 4958>,
			<12380 8025 5730 5025 4969 4962>,
			<19407 9840 6021 5041 4977 4968>,
			<44210 15120 6736 5073 5003 5001>,
			<44210 15120 6736 5073 5003 5001>,
			<44210 15120 6736 5073 5003 5001>;
	};

};

qcom,4391492_BBK_ATL_PD1965_5000mAH_PMI63_SecondSupply {
    /* 4391492_BBK_ATL_PD1965_5000mAH_PMI632_averaged_MasterSlave_Jan2th2020 */
    qcom,max-voltage-uv = <4430000>;
    qcom,fg-cc-cv-threshold-uv = <4420000>;
    qcom,fastchg-current-ma = <700>;
    qcom,batt-id-kohm = <200>;
    qcom,nom-batt-capacity-mah = <4880>;/*min value*/
    qcom,battery-beta = <3440>;
    qcom,battery-therm-kohm = <10>;
    qcom,battery-type = "vivo_PD2006F_EX_batterydata:batid(200)";
    qcom,qg-batt-profile-ver = <100>;

	qcom,fcc1-temp-lut {
		qcom,lut-col-legend = <0 10 25 40 50>;
		qcom,lut-data = <4801 4886 4991 5030 5041>;
	};

	qcom,fcc2-temp-lut {
		qcom,lut-col-legend = <(-10) 0 10 25 40 50>;
		qcom,lut-data = <4944 4949 4968 5003 4978 4977>;
	};

	qcom,pc-temp-v1-lut {
		qcom,lut-col-legend = <0 10 25 40 50>;
		qcom,lut-row-legend = <10000 9800 9600 9400 9200>,
			<9000 8800 8600 8400 8200>,
			<8000 7800 7600 7400 7200>,
			<7000 6800 6600 6400 6200>,
			<6000 5800 5600 5400 5200>,
			<5000 4800 4600 4400 4200>,
			<4000 3800 3600 3400 3200>,
			<3000 2800 2600 2400 2200>,
			<2000 1800 1600 1400 1200>,
			<1000 900 800 700 600>,
			<500 400 300 200 100>,
			<0>;
		qcom,lut-data = <44061 44137 44195 44220 44225>,
			<43896 43960 44010 44027 44033>,
			<43679 43763 43816 43839 43847>,
			<43447 43549 43614 43642 43653>,
			<43217 43327 43400 43431 43447>,
			<42980 43094 43178 43212 43231>,
			<42744 42856 42942 42983 43006>,
			<42505 42617 42700 42747 42770>,
			<42269 42378 42459 42508 42533>,
			<42038 42140 42218 42266 42293>,
			<41811 41906 41979 42024 42052>,
			<41590 41675 41742 41787 41815>,
			<41372 41451 41509 41553 41581>,
			<41161 41235 41284 41323 41352>,
			<40958 41023 41065 41099 41129>,
			<40764 40817 40854 40882 40912>,
			<40574 40617 40648 40674 40702>,
			<40386 40427 40449 40474 40498>,
			<40200 40257 40265 40284 40304>,
			<40005 40080 40095 40109 40126>,
			<39791 39852 39909 39929 39945>,
			<39579 39578 39667 39704 39726>,
			<39384 39352 39415 39455 39481>,
			<39195 39187 39218 39246 39272>,
			<39039 39048 39057 39074 39097>,
			<38925 38925 38916 38924 38944>,
			<38829 38816 38792 38797 38811>,
			<38742 38719 38683 38686 38693>,
			<38661 38630 38584 38583 38584>,
			<38589 38549 38493 38484 38482>,
			<38526 38479 38412 38394 38388>,
			<38470 38415 38337 38310 38301>,
			<38419 38359 38270 38234 38221>,
			<38373 38308 38213 38167 38149>,
			<38330 38263 38167 38111 38086>,
			<38293 38219 38120 38055 38021>,
			<38260 38182 38072 37992 37944>,
			<38217 38138 38020 37924 37857>,
			<38138 38063 37948 37845 37767>,
			<38027 37952 37847 37750 37671>,
			<37903 37828 37733 37642 37564>,
			<37758 37687 37608 37516 37436>,
			<37610 37532 37467 37374 37293>,
			<37462 37353 37295 37212 37130>,
			<37305 37212 37154 37083 37014>,
			<37205 37125 37081 37014 36951>,
			<37170 37099 37059 36995 36933>,
			<37142 37079 37039 36982 36918>,
			<37109 37057 37014 36958 36891>,
			<37015 36951 36890 36798 36701>,
			<36674 36585 36528 36432 36331>,
			<36193 36111 36051 35952 35852>,
			<35580 35489 35438 35337 35235>,
			<34742 34642 34603 34498 34396>,
			<33413 33295 33303 33195 33092>,
			<30000 30000 30000 30000 30000>;
	};

	qcom,pc-temp-v2-lut {
		qcom,lut-col-legend = <(-10) 0 10 25 40 50>;
		qcom,lut-row-legend = <10000 9800 9600 9400 9200 9000>,
			<8800 8600 8400 8200 8000 7800>,
			<7600 7400 7200 7000 6800 6600>,
			<6400 6200 6000 5800 5600 5400>,
			<5200 5000 4800 4600 4400 4200>,
			<4000 3800 3600 3400 3200 3000>,
			<2800 2600 2400 2200 2000 1800>,
			<1600 1400 1200 1000 900 800>,
			<700 600 500 400 300 200>,
			<100 0>;
		qcom,lut-data = <44225 44175 44175 44190 44110 44115>,
			<43838 43904 43937 43970 43898 43903>,
			<43495 43643 43705 43752 43685 43689>,
			<43207 43396 43481 43536 43470 43476>,
			<42966 43163 43266 43323 43256 43263>,
			<42730 42928 43047 43104 43035 43044>,
			<42478 42681 42813 42871 42803 42814>,
			<42215 42431 42573 42630 42565 42576>,
			<41919 42185 42335 42390 42326 42339>,
			<41550 41945 42097 42146 42085 42099>,
			<41263 41709 41862 41906 41848 41863>,
			<41143 41470 41628 41668 41613 41629>,
			<41062 41236 41399 41435 41383 41399>,
			<40902 41023 41175 41207 41158 41174>,
			<40518 40835 40957 40983 40937 40953>,
			<40121 40642 40744 40766 40724 40740>,
			<39889 40420 40539 40557 40519 40533>,
			<39705 40177 40335 40354 40321 40333>,
			<39488 39932 40121 40159 40130 40142>,
			<39212 39677 39893 39974 39951 39964>,
			<38947 39429 39659 39773 39758 39773>,
			<38733 39198 39415 39519 39511 39528>,
			<38548 38981 39170 39253 39243 39263>,
			<38415 38794 38971 39051 39041 39061>,
			<38323 38635 38812 38889 38888 38907>,
			<38250 38492 38673 38749 38755 38774>,
			<38189 38356 38545 38623 38632 38650>,
			<38138 38228 38430 38511 38522 38538>,
			<38087 38129 38323 38406 38419 38434>,
			<38037 38055 38221 38307 38323 38335>,
			<37986 37993 38127 38217 38234 38245>,
			<37935 37940 38042 38134 38156 38163>,
			<37882 37893 37963 38057 38083 38086>,
			<37825 37845 37895 37982 38007 38003>,
			<37764 37798 37839 37910 37929 37914>,
			<37698 37748 37785 37835 37844 37817>,
			<37628 37688 37731 37753 37743 37703>,
			<37553 37620 37677 37667 37630 37578>,
			<37471 37539 37610 37583 37529 37469>,
			<37379 37442 37523 37501 37442 37380>,
			<37278 37330 37417 37409 37350 37287>,
			<37163 37201 37291 37295 37233 37167>,
			<37030 37051 37143 37164 37100 37031>,
			<36905 36898 36987 36993 36951 36888>,
			<36790 36757 36865 36914 36871 36810>,
			<36703 36665 36807 36886 36848 36787>,
			<36663 36626 36777 36869 36829 36768>,
			<36619 36577 36729 36840 36800 36740>,
			<36552 36490 36653 36783 36728 36646>,
			<36437 36316 36465 36614 36486 36366>,
			<36149 35975 36069 36201 36045 35916>,
			<35648 35477 35504 35666 35485 35348>,
			<34957 34800 34782 34970 34754 34598>,
			<33964 33826 33786 34010 33704 33557>,
			<32369 32283 32339 32559 32419 32087>,
			<29589 29119 29003 29070 29002 29003>;
	};

	qcom,pc-temp-z1-lut {
		qcom,lut-col-legend = <0 10 25 40 50>;
		qcom,lut-row-legend = <10000 9800 9600 9400 9200>,
			<9000 8800 8600 8400 8200>,
			<8000 7800 7600 7400 7200>,
			<7000 6800 6600 6400 6200>,
			<6000 5800 5600 5400 5200>,
			<5000 4800 4600 4400 4200>,
			<4000 3800 3600 3400 3200>,
			<3000 2800 2600 2400 2200>,
			<2000 1800 1600 1400 1200>,
			<1000 900 800 700 600>,
			<500 400 300 200 100>,
			<0>;
		qcom,lut-data = <12152 11640 11121 10911 10832>,
			<12122 11562 11036 10812 10751>,
			<12087 11520 10979 10773 10727>,
			<12059 11491 10965 10762 10720>,
			<12039 11480 10958 10759 10719>,
			<12017 11483 10953 10757 10717>,
			<12010 11488 10948 10753 10715>,
			<12010 11487 10944 10750 10713>,
			<12010 11472 10939 10747 10711>,
			<12009 11459 10934 10744 10710>,
			<12003 11460 10930 10742 10710>,
			<12000 11463 10926 10741 10709>,
			<12001 11463 10924 10741 10709>,
			<12001 11459 10923 10741 10709>,
			<12001 11455 10924 10742 10708>,
			<11996 11455 10925 10742 10707>,
			<11991 11456 10923 10741 10708>,
			<11991 11456 10921 10740 10710>,
			<11991 11450 10922 10739 10712>,
			<11993 11445 10926 10741 10712>,
			<12001 11449 10929 10742 10713>,
			<12010 11463 10931 10743 10713>,
			<12011 11469 10933 10744 10715>,
			<12003 11465 10936 10745 10716>,
			<12000 11460 10940 10748 10717>,
			<12013 11460 10944 10750 10718>,
			<12030 11463 10946 10753 10720>,
			<12033 11467 10948 10756 10723>,
			<12027 11469 10952 10759 10725>,
			<12022 11472 10958 10761 10727>,
			<12029 11473 10963 10764 10729>,
			<12046 11474 10966 10767 10732>,
			<12053 11475 10968 10771 10734>,
			<12042 11474 10971 10773 10737>,
			<12029 11474 10977 10775 10739>,
			<12030 11475 10982 10777 10741>,
			<12042 11483 10988 10781 10743>,
			<12051 11491 10994 10786 10746>,
			<12052 11495 10997 10788 10747>,
			<12052 11497 10999 10789 10749>,
			<12056 11500 11001 10789 10751>,
			<12074 11501 11002 10790 10753>,
			<12080 11504 11003 10792 10755>,
			<12076 11507 11005 10793 10755>,
			<12070 11519 11008 10794 10755>,
			<12063 11504 11011 10796 10753>,
			<12067 11500 11014 10797 10757>,
			<12065 11501 11016 10801 10755>,
			<12079 11501 11017 10801 10758>,
			<12078 11508 11019 10805 10761>,
			<12084 11524 11024 10808 10762>,
			<12106 11534 11030 10810 10766>,
			<12112 11537 11039 10818 10771>,
			<12156 11578 11050 10824 10776>,
			<12156 11578 11050 10824 10776>,
			<12156 11578 11050 10824 10776>;
	};

	qcom,pc-temp-z2-lut {
		qcom,lut-col-legend = <0 10 25 40 50>;
		qcom,lut-row-legend = <10000 9800 9600 9400 9200>,
			<9000 8800 8600 8400 8200>,
			<8000 7800 7600 7400 7200>,
			<7000 6800 6600 6400 6200>,
			<6000 5800 5600 5400 5200>,
			<5000 4800 4600 4400 4200>,
			<4000 3800 3600 3400 3200>,
			<3000 2800 2600 2400 2200>,
			<2000 1800 1600 1400 1200>,
			<1000 900 800 700 600>,
			<500 400 300 200 100>,
			<0>;
		qcom,lut-data = <11316 10650 11293 11777 11181>,
			<10578 10735 11148 11036 11105>,
			<10543 10721 11049 11125 11113>,
			<10542 10695 11020 11162 11126>,
			<10542 10684 11008 11157 11158>,
			<10543 10694 11002 11146 11195>,
			<10545 10711 11012 11109 11207>,
			<10553 10717 11029 11034 11203>,
			<10562 10720 11032 11011 11204>,
			<10565 10722 11036 11112 11229>,
			<10566 10728 11035 11212 11256>,
			<10567 10735 11027 11179 11246>,
			<10573 10737 11020 11081 11206>,
			<10581 10736 11024 11047 11189>,
			<10581 10736 11045 11071 11218>,
			<10572 10731 11057 11103 11253>,
			<10563 10718 11043 11128 11264>,
			<10559 10709 11023 11150 11275>,
			<10557 10703 11019 11154 11270>,
			<10550 10699 11018 11134 11245>,
			<10497 10695 11018 11116 11211>,
			<10441 10683 11015 11114 11168>,
			<10442 10671 11008 11109 11109>,
			<10467 10650 10996 11103 11075>,
			<10482 10630 10965 11092 11057>,
			<10474 10626 10948 11080 11047>,
			<10461 10627 10952 11065 11054>,
			<10458 10628 10958 11044 11077>,
			<10463 10636 10958 11039 11104>,
			<10470 10648 10950 11039 11142>,
			<10479 10654 10945 11050 11180>,
			<10491 10656 10974 11088 11218>,
			<10498 10658 11022 11137 11270>,
			<10501 10661 11049 11160 11306>,
			<10504 10664 11067 11139 11328>,
			<10509 10665 11082 11135 11353>,
			<10517 10669 11099 11220 11445>,
			<10526 10676 11121 11347 11583>,
			<10547 10704 11159 11404 11619>,
			<10572 10759 11234 11409 11570>,
			<10576 10779 11276 11397 11529>,
			<10560 10770 11237 11349 11467>,
			<10579 10766 11198 11296 11390>,
			<10784 10792 11224 11289 11356>,
			<11474 10833 11233 11304 11382>,
			<11833 10789 11240 11296 11320>,
			<11508 10793 11214 11209 11379>,
			<11152 10830 11172 11304 11450>,
			<11789 11061 11135 11310 11483>,
			<10999 10982 11277 11206 11127>,
			<10491 10912 11162 11075 11000>,
			<10250 10799 11088 10969 10908>,
			<9946 10805 11051 10910 10902>,
			<9604 10533 10977 10881 10801>,
			<9604 10533 10977 10881 10801>,
			<9604 10533 10977 10881 10801>;
	};

	qcom,pc-temp-z3-lut {
		qcom,lut-col-legend = <0 10 25 40 50>;
		qcom,lut-row-legend = <10000 9800 9600 9400 9200>,
			<9000 8800 8600 8400 8200>,
			<8000 7800 7600 7400 7200>,
			<7000 6800 6600 6400 6200>,
			<6000 5800 5600 5400 5200>,
			<5000 4800 4600 4400 4200>,
			<4000 3800 3600 3400 3200>,
			<3000 2800 2600 2400 2200>,
			<2000 1800 1600 1400 1200>,
			<1000 900 800 700 600>,
			<500 400 300 200 100>,
			<0>;
		qcom,lut-data = <19258 19323 19328 19307 19299>,
			<19291 19439 19376 19327 19315>,
			<19488 19498 19406 19338 19319>,
			<19653 19537 19408 19343 19320>,
			<19674 19552 19402 19343 19320>,
			<19685 19547 19398 19343 19320>,
			<19687 19538 19396 19340 19320>,
			<19679 19529 19394 19332 19319>,
			<19667 19519 19390 19328 19318>,
			<19659 19513 19379 19327 19318>,
			<19652 19513 19374 19327 19319>,
			<19647 19513 19375 19327 19318>,
			<19641 19512 19376 19327 19317>,
			<19636 19503 19373 19327 19315>,
			<19635 19496 19359 19325 19311>,
			<19639 19499 19351 19322 19307>,
			<19642 19507 19353 19319 19306>,
			<19642 19510 19355 19314 19305>,
			<19642 19502 19355 19312 19304>,
			<19643 19495 19356 19312 19302>,
			<19660 19500 19358 19314 19301>,
			<19680 19521 19376 19324 19306>,
			<19687 19537 19399 19345 19321>,
			<19692 19547 19404 19353 19327>,
			<19695 19553 19404 19354 19328>,
			<19697 19552 19404 19355 19329>,
			<19699 19547 19405 19349 19328>,
			<19698 19542 19405 19336 19326>,
			<19691 19537 19403 19331 19325>,
			<19682 19533 19395 19330 19325>,
			<19674 19527 19389 19330 19324>,
			<19666 19521 19388 19330 19323>,
			<19661 19515 19387 19331 19320>,
			<19657 19511 19385 19331 19317>,
			<19654 19508 19379 19329 19314>,
			<19652 19506 19376 19326 19312>,
			<19649 19506 19377 19325 19312>,
			<19646 19506 19379 19324 19313>,
			<19638 19500 19379 19324 19314>,
			<19628 19489 19375 19322 19314>,
			<19624 19484 19371 19322 19315>,
			<19624 19487 19367 19325 19315>,
			<19582 19488 19364 19328 19317>,
			<19282 19476 19365 19327 19321>,
			<19259 19451 19364 19324 19315>,
			<19258 19450 19348 19320 19307>,
			<19258 19447 19349 19321 19305>,
			<19258 19433 19351 19313 19303>,
			<19258 19348 19347 19306 19300>,
			<19258 19379 19344 19323 19318>,
			<19259 19408 19356 19327 19321>,
			<19260 19288 19358 19332 19322>,
			<19262 19314 19352 19329 19326>,
			<19266 19311 19341 19334 19328>,
			<19266 19311 19341 19334 19328>,
			<19266 19311 19341 19334 19328>;
	};

	qcom,pc-temp-z4-lut {
		qcom,lut-col-legend = <0 10 25 40 50>;
		qcom,lut-row-legend = <10000 9800 9600 9400 9200>,
			<9000 8800 8600 8400 8200>,
			<8000 7800 7600 7400 7200>,
			<7000 6800 6600 6400 6200>,
			<6000 5800 5600 5400 5200>,
			<5000 4800 4600 4400 4200>,
			<4000 3800 3600 3400 3200>,
			<3000 2800 2600 2400 2200>,
			<2000 1800 1600 1400 1200>,
			<1000 900 800 700 600>,
			<500 400 300 200 100>,
			<0>;
		qcom,lut-data = <15453 15196 14961 14781 14759>,
			<15468 15215 14956 14833 14781>,
			<15391 15195 14945 14808 14764>,
			<15294 15105 14926 14791 14751>,
			<15193 15027 14887 14782 14745>,
			<15085 14988 14856 14775 14741>,
			<15031 14958 14841 14769 14736>,
			<15011 14939 14830 14765 14732>,
			<14997 14927 14821 14760 14727>,
			<14983 14916 14814 14753 14721>,
			<14969 14901 14806 14746 14715>,
			<14960 14885 14794 14739 14711>,
			<14954 14876 14782 14732 14707>,
			<14949 14869 14777 14726 14703>,
			<14948 14866 14775 14720 14699>,
			<14948 14869 14773 14715 14695>,
			<14948 14875 14766 14709 14690>,
			<14950 14877 14758 14704 14683>,
			<14958 14866 14754 14700 14679>,
			<14972 14853 14751 14696 14677>,
			<15025 14904 14751 14694 14676>,
			<15087 15063 14804 14714 14689>,
			<15120 15140 14881 14759 14723>,
			<15154 15092 14891 14773 14737>,
			<15170 15021 14876 14772 14738>,
			<15131 14984 14859 14771 14738>,
			<15065 14960 14842 14768 14736>,
			<15036 14945 14826 14765 14730>,
			<15023 14935 14817 14760 14724>,
			<15016 14928 14810 14751 14717>,
			<15014 14924 14805 14742 14710>,
			<15012 14922 14800 14733 14705>,
			<15011 14921 14796 14726 14700>,
			<15010 14919 14792 14722 14696>,
			<15009 14918 14788 14719 14693>,
			<15005 14916 14786 14718 14691>,
			<14996 14911 14793 14728 14697>,
			<14987 14905 14805 14747 14711>,
			<14980 14900 14807 14751 14714>,
			<14973 14895 14807 14745 14710>,
			<14961 14887 14806 14737 14705>,
			<14939 14869 14793 14729 14701>,
			<14965 14855 14780 14723 14698>,
			<15203 14850 14779 14726 14703>,
			<15177 14825 14771 14725 14703>,
			<15146 14784 14752 14714 14691>,
			<15137 14766 14729 14701 14679>,
			<15126 14763 14705 14683 14663>,
			<15115 14839 14695 14679 14658>,
			<15115 14813 14715 14682 14663>,
			<15136 14797 14705 14679 14662>,
			<15144 14920 14701 14674 14662>,
			<15151 14897 14707 14676 14659>,
			<15181 14909 14717 14673 14659>,
			<15181 14909 14717 14673 14659>,
			<15181 14909 14717 14673 14659>;
	};

	qcom,pc-temp-z5-lut {
		qcom,lut-col-legend = <0 10 25 40 50>;
		qcom,lut-row-legend = <10000 9800 9600 9400 9200>,
			<9000 8800 8600 8400 8200>,
			<8000 7800 7600 7400 7200>,
			<7000 6800 6600 6400 6200>,
			<6000 5800 5600 5400 5200>,
			<5000 4800 4600 4400 4200>,
			<4000 3800 3600 3400 3200>,
			<3000 2800 2600 2400 2200>,
			<2000 1800 1600 1400 1200>,
			<1000 900 800 700 600>,
			<500 400 300 200 100>,
			<0>;
		qcom,lut-data = <11158 12046 13940 14471 15125>,
			<11606 14259 16208 16833 17677>,
			<13986 16162 17732 17960 18263>,
			<16501 17974 18122 18545 18557>,
			<18058 18936 18261 18831 18767>,
			<19333 19189 18360 18990 18904>,
			<19700 19332 18472 18672 18957>,
			<19583 19284 18558 17741 18921>,
			<19428 18919 18408 17324 18920>,
			<19333 18663 17717 17467 19171>,
			<19240 18914 17321 17644 19460>,
			<19194 19378 17666 17759 19500>,
			<19112 19474 18146 18047 19457>,
			<19019 19128 17971 18160 19382>,
			<19144 18814 16869 18180 18826>,
			<19663 19161 16228 18178 18225>,
			<20061 20028 16501 17923 18195>,
			<19866 20331 16930 17359 18323>,
			<19399 19818 17206 17139 18396>,
			<19319 19222 17681 17429 18363>,
			<21137 19107 17901 17728 18248>,
			<23141 19215 17668 17686 17948>,
			<22748 19288 17346 17573 17457>,
			<20514 19219 17200 17602 17242>,
			<19211 19165 17184 17711 17187>,
			<19788 19411 17310 17778 17160>,
			<20863 20291 18077 17452 17313>,
			<21650 21201 19141 16765 17734>,
			<22341 22012 19567 16600 18102>,
			<22777 22724 19675 16978 19032>,
			<22859 22962 19910 17581 19849>,
			<22899 23042 20865 18552 20166>,
			<22938 23101 22060 19846 20721>,
			<22988 23156 22509 20636 21279>,
			<23029 23206 22547 21269 21955>,
			<23043 23303 22561 21610 22371>,
			<23030 23577 22883 21099 21798>,
			<23023 23798 23285 20129 20634>,
			<23024 23535 23227 19785 20348>,
			<23000 22858 22500 19417 20713>,
			<22928 22616 21665 19274 21070>,
			<22801 23027 20882 19855 21409>,
			<21309 23190 20236 20406 21801>,
			<12195 21264 19817 19776 22252>,
			<11411 19246 19595 18776 20258>,
			<11333 19812 18166 18422 18025>,
			<11317 19801 19192 19856 18766>,
			<11291 18707 21166 19869 20950>,
			<11233 13373 21303 19330 21183>,
			<11246 15041 17862 19535 22967>,
			<11268 15831 18956 19538 22898>,
			<11213 11840 18776 20570 22999>,
			<11137 12141 17447 19547 24357>,
			<11084 11961 16052 20015 23848>,
			<11084 11961 16052 20015 23848>,
			<11084 11961 16052 20015 23848>;
	};

	qcom,pc-temp-z6-lut {
		qcom,lut-col-legend = <0 10 25 40 50>;
		qcom,lut-row-legend = <10000 9800 9600 9400 9200>,
			<9000 8800 8600 8400 8200>,
			<8000 7800 7600 7400 7200>,
			<7000 6800 6600 6400 6200>,
			<6000 5800 5600 5400 5200>,
			<5000 4800 4600 4400 4200>,
			<4000 3800 3600 3400 3200>,
			<3000 2800 2600 2400 2200>,
			<2000 1800 1600 1400 1200>,
			<1000 900 800 700 600>,
			<500 400 300 200 100>,
			<0>;
		qcom,lut-data = <15443 14980 14630 14494 14470>,
			<15409 15014 14637 14510 14468>,
			<15404 15009 14636 14499 14459>,
			<15398 14969 14626 14491 14454>,
			<15357 14929 14604 14487 14452>,
			<15276 14901 14586 14483 14450>,
			<15224 14877 14577 14478 14447>,
			<15200 14858 14570 14472 14444>,
			<15181 14843 14562 14467 14441>,
			<15165 14830 14553 14463 14439>,
			<15150 14820 14545 14459 14436>,
			<15139 14811 14540 14456 14434>,
			<15129 14802 14536 14453 14431>,
			<15122 14792 14530 14450 14429>,
			<15120 14786 14523 14447 14425>,
			<15120 14788 14517 14443 14421>,
			<15120 14793 14514 14439 14418>,
			<15121 14794 14512 14434 14415>,
			<15125 14785 14512 14432 14413>,
			<15133 14776 14511 14431 14412>,
			<15165 14802 14512 14430 14410>,
			<15204 14885 14545 14444 14419>,
			<15228 14925 14592 14476 14443>,
			<15251 14910 14598 14487 14453>,
			<15262 14886 14593 14487 14454>,
			<15249 14872 14587 14487 14454>,
			<15227 14861 14581 14484 14453>,
			<15216 14854 14575 14476 14449>,
			<15211 14850 14570 14470 14446>,
			<15208 14846 14563 14466 14443>,
			<15206 14844 14559 14462 14440>,
			<15206 14841 14558 14460 14437>,
			<15206 14840 14557 14458 14434>,
			<15208 14840 14555 14456 14431>,
			<15210 14840 14552 14453 14428>,
			<15212 14841 14550 14452 14426>,
			<15215 14843 14555 14456 14430>,
			<15216 14845 14562 14465 14436>,
			<15217 14844 14564 14466 14438>,
			<15219 14841 14563 14463 14437>,
			<15220 14839 14561 14460 14435>,
			<15223 14838 14554 14459 14434>,
			<15221 14836 14548 14458 14434>,
			<15191 14834 14549 14459 14438>,
			<15183 14819 14547 14458 14436>,
			<15181 14805 14532 14450 14426>,
			<15180 14799 14522 14445 14420>,
			<15181 14793 14514 14434 14412>,
			<15182 14786 14508 14429 14409>,
			<15196 14799 14518 14440 14421>,
			<15218 14813 14521 14441 14423>,
			<15233 14812 14523 14443 14424>,
			<15255 14826 14525 14444 14427>,
			<15297 14844 14528 14447 14429>,
			<15297 14844 14528 14447 14429>,
			<15297 14844 14528 14447 14429>;
	};

	qcom,pc-temp-y1-lut {
		qcom,lut-col-legend = <(-10) 0 10 25 40 50>;
		qcom,lut-row-legend = <10000 9800 9600 9400 9200 9000>,
			<8800 8600 8400 8200 8000 7800>,
			<7600 7400 7200 7000 6800 6600>,
			<6400 6200 6000 5800 5600 5400>,
			<5200 5000 4800 4600 4400 4200>,
			<4000 3800 3600 3400 3200 3000>,
			<2800 2600 2400 2200 2000 1800>,
			<1600 1400 1200 1000 900 800>,
			<700 600 500 400 300 200>,
			<100 0>;
		qcom,lut-data = <5866 5422 5158 4850 4705 4669>,
			<5876 5418 5147 4841 4702 4668>,
			<5881 5413 5134 4832 4698 4668>,
			<5884 5407 5121 4823 4694 4667>,
			<5885 5402 5111 4816 4691 4667>,
			<5886 5400 5106 4810 4688 4666>,
			<5878 5400 5106 4807 4687 4665>,
			<5866 5401 5108 4804 4685 4663>,
			<5865 5401 5106 4800 4684 4662>,
			<5881 5401 5101 4796 4683 4661>,
			<5893 5401 5096 4792 4683 4660>,
			<5888 5403 5093 4789 4681 4660>,
			<5877 5406 5090 4786 4678 4659>,
			<5874 5407 5090 4786 4676 4660>,
			<5874 5402 5091 4788 4675 4661>,
			<5874 5398 5093 4789 4675 4662>,
			<5877 5399 5093 4791 4676 4662>,
			<5884 5402 5092 4792 4679 4661>,
			<5886 5403 5093 4793 4680 4661>,
			<5881 5402 5094 4795 4681 4662>,
			<5877 5402 5096 4796 4682 4662>,
			<5878 5403 5097 4797 4682 4663>,
			<5879 5406 5099 4799 4682 4664>,
			<5882 5409 5101 4801 4683 4664>,
			<5901 5411 5104 4802 4683 4664>,
			<5921 5413 5106 4804 4684 4665>,
			<5921 5415 5107 4805 4685 4666>,
			<5918 5417 5107 4807 4687 4668>,
			<5913 5418 5108 4808 4688 4669>,
			<5897 5414 5105 4810 4689 4669>,
			<5882 5409 5102 4812 4690 4670>,
			<5886 5409 5105 4814 4692 4671>,
			<5902 5410 5113 4817 4695 4672>,
			<5909 5411 5115 4819 4697 4673>,
			<5896 5415 5113 4823 4701 4674>,
			<5880 5419 5111 4826 4704 4675>,
			<5880 5418 5112 4827 4706 4676>,
			<5886 5414 5114 4828 4708 4679>,
			<5890 5412 5115 4830 4708 4680>,
			<5889 5413 5115 4833 4709 4681>,
			<5888 5414 5115 4836 4710 4682>,
			<5884 5415 5121 4837 4713 4683>,
			<5876 5416 5134 4838 4716 4685>,
			<5875 5420 5132 4838 4716 4685>,
			<5880 5427 5131 4843 4716 4685>,
			<5891 5426 5144 4846 4718 4688>,
			<5890 5435 5141 4852 4718 4689>,
			<5890 5446 5134 4853 4721 4689>,
			<5928 5436 5136 4855 4721 4688>,
			<5898 5452 5140 4851 4720 4689>,
			<5901 5462 5143 4857 4721 4691>,
			<5936 5486 5147 4862 4725 4692>,
			<5968 5480 5163 4867 4729 4695>,
			<5880 5483 5180 4875 4735 4701>,
			<5880 5483 5180 4875 4735 4701>,
			<5880 5483 5180 4875 4735 4701>;
	};

	qcom,pc-temp-y2-lut {
		qcom,lut-col-legend = <(-10) 0 10 25 40 50>;
		qcom,lut-row-legend = <10000 9800 9600 9400 9200 9000>,
			<8800 8600 8400 8200 8000 7800>,
			<7600 7400 7200 7000 6800 6600>,
			<6400 6200 6000 5800 5600 5400>,
			<5200 5000 4800 4600 4400 4200>,
			<4000 3800 3600 3400 3200 3000>,
			<2800 2600 2400 2200 2000 1800>,
			<1600 1400 1200 1000 900 800>,
			<700 600 500 400 300 200>,
			<100 0>;
		qcom,lut-data = <9643 10863 11325 11833 11821 12383>,
			<9643 10886 11297 11772 11792 12238>,
			<9643 10907 11271 11699 11763 12078>,
			<9788 10924 11246 11627 11736 11926>,
			<10004 10936 11223 11570 11711 11804>,
			<10107 10940 11203 11542 11690 11733>,
			<10237 10936 11182 11542 11672 11710>,
			<10446 10929 11165 11547 11655 11704>,
			<10426 10925 11164 11537 11633 11702>,
			<10015 10923 11179 11514 11599 11688>,
			<9700 10924 11191 11501 11570 11678>,
			<9926 10932 11192 11532 11554 11655>,
			<10380 10948 11191 11578 11552 11614>,
			<10465 10982 11194 11586 11576 11601>,
			<10054 11088 11209 11580 11657 11598>,
			<9700 11170 11234 11573 11711 11596>,
			<9684 11164 11291 11569 11696 11628>,
			<9682 11143 11368 11572 11669 11684>,
			<9679 11126 11385 11603 11679 11693>,
			<9674 11101 11360 11698 11789 11656>,
			<9670 11083 11340 11760 11887 11628>,
			<9667 11093 11348 11767 11914 11718>,
			<9666 11121 11371 11771 11926 11901>,
			<9664 11142 11398 11772 11929 12000>,
			<9663 11155 11442 11779 11934 12079>,
			<9661 11163 11482 11785 11946 12128>,
			<9660 11088 11498 11783 11982 12129>,
			<9659 10845 11510 11779 12032 12125>,
			<9658 10593 11518 11791 12046 12130>,
			<9658 10291 11531 11848 12064 12167>,
			<9657 10028 11536 11887 12092 12208>,
			<9657 9923 11522 11881 12148 12281>,
			<9656 9862 11496 11865 12228 12394>,
			<9656 9812 11478 11858 12247 12417>,
			<9655 9764 11470 11854 12221 12338>,
			<9655 9725 11460 11857 12184 12263>,
			<9655 9704 11433 11905 12128 12276>,
			<9655 9689 11376 11967 12052 12330>,
			<9655 9680 11310 11968 12016 12331>,
			<9655 9673 11234 11923 12007 12236>,
			<9655 9668 11141 11889 12008 12143>,
			<9655 9664 11029 11897 12026 12059>,
			<9654 9661 10892 11912 12043 11954>,
			<9654 9659 10728 11841 11957 12038>,
			<9654 9658 10565 11738 11850 12125>,
			<9654 9656 10476 11679 11873 12005>,
			<9653 9656 10385 11758 11851 11882>,
			<9653 9655 10185 11740 11736 11687>,
			<9653 9655 10035 11593 11707 11618>,
			<9652 9654 9823 11562 11682 11685>,
			<9650 9653 9730 11449 11604 11615>,
			<9650 9652 9683 11385 11542 11492>,
			<9649 9651 9664 11218 11436 11359>,
			<9649 9655 9665 11146 11230 11183>,
			<9649 9655 9665 11146 11230 11183>,
			<9649 9655 9665 11146 11230 11183>;
	};

	qcom,pc-temp-y3-lut {
		qcom,lut-col-legend = <(-10) 0 10 25 40 50>;
		qcom,lut-row-legend = <10000 9800 9600 9400 9200 9000>,
			<8800 8600 8400 8200 8000 7800>,
			<7600 7400 7200 7000 6800 6600>,
			<6400 6200 6000 5800 5600 5400>,
			<5200 5000 4800 4600 4400 4200>,
			<4000 3800 3600 3400 3200 3000>,
			<2800 2600 2400 2200 2000 1800>,
			<1600 1400 1200 1000 900 800>,
			<700 600 500 400 300 200>,
			<100 0>;
		qcom,lut-data = <13657 13395 13321 13289 13273 13269>,
			<13659 13398 13322 13288 13272 13269>,
			<13655 13400 13325 13287 13272 13269>,
			<13648 13402 13328 13286 13272 13269>,
			<13639 13403 13330 13285 13272 13270>,
			<13629 13403 13331 13285 13272 13270>,
			<13617 13403 13332 13285 13273 13270>,
			<13601 13402 13332 13285 13275 13271>,
			<13580 13402 13332 13285 13275 13271>,
			<13546 13405 13333 13284 13275 13272>,
			<13521 13409 13334 13283 13274 13273>,
			<13517 13414 13335 13283 13274 13273>,
			<13515 13420 13335 13285 13274 13273>,
			<13515 13420 13336 13285 13274 13273>,
			<13527 13409 13337 13286 13274 13273>,
			<13540 13397 13337 13287 13275 13272>,
			<13548 13392 13337 13289 13276 13272>,
			<13555 13388 13335 13291 13278 13273>,
			<13555 13382 13333 13294 13280 13273>,
			<13536 13373 13329 13297 13283 13275>,
			<13514 13363 13325 13298 13285 13277>,
			<13506 13356 13320 13294 13281 13275>,
			<13501 13351 13315 13289 13274 13270>,
			<13500 13346 13312 13286 13272 13269>,
			<13529 13343 13309 13284 13272 13269>,
			<13575 13340 13308 13283 13272 13270>,
			<13623 13331 13308 13283 13272 13270>,
			<13682 13313 13308 13283 13271 13269>,
			<13745 13296 13307 13283 13271 13269>,
			<13811 13277 13305 13282 13271 13270>,
			<13885 13264 13303 13282 13271 13270>,
			<13972 13271 13304 13282 13272 13269>,
			<14074 13297 13305 13282 13273 13269>,
			<14182 13319 13306 13282 13274 13269>,
			<14295 13332 13305 13281 13273 13268>,
			<14413 13344 13305 13281 13273 13268>,
			<14535 13361 13306 13278 13272 13268>,
			<14663 13383 13307 13276 13271 13268>,
			<14783 13411 13309 13275 13271 13269>,
			<14893 13451 13310 13275 13271 13269>,
			<14997 13506 13312 13276 13271 13270>,
			<15094 13582 13316 13276 13271 13270>,
			<15184 13694 13322 13276 13271 13270>,
			<15280 13835 13329 13276 13271 13270>,
			<15390 14018 13340 13279 13272 13270>,
			<15548 14243 13354 13282 13272 13271>,
			<15624 14324 13356 13284 13274 13273>,
			<15813 14506 13366 13284 13276 13275>,
			<16086 14725 13388 13290 13280 13275>,
			<16533 15024 13414 13293 13278 13274>,
			<17955 15431 13458 13290 13277 13275>,
			<21143 16038 13556 13294 13278 13276>,
			<28534 17939 13794 13297 13280 13276>,
			<46189 22216 14569 13304 13283 13277>,
			<46189 22216 14569 13304 13283 13277>,
			<46189 22216 14569 13304 13283 13277>;
	};

	qcom,pc-temp-y4-lut {
		qcom,lut-col-legend = <(-10) 0 10 25 40 50>;
		qcom,lut-row-legend = <10000 9800 9600 9400 9200 9000>,
			<8800 8600 8400 8200 8000 7800>,
			<7600 7400 7200 7000 6800 6600>,
			<6400 6200 6000 5800 5600 5400>,
			<5200 5000 4800 4600 4400 4200>,
			<4000 3800 3600 3400 3200 3000>,
			<2800 2600 2400 2200 2000 1800>,
			<1600 1400 1200 1000 900 800>,
			<700 600 500 400 300 200>,
			<100 0>;
		qcom,lut-data = <17314 16785 16600 16501 16457 16446>,
			<17470 16872 16638 16500 16458 16446>,
			<17621 16974 16670 16499 16459 16447>,
			<17751 17071 16695 16499 16459 16447>,
			<17843 17145 16711 16499 16459 16447>,
			<17880 17176 16718 16499 16460 16448>,
			<17849 17165 16711 16500 16459 16448>,
			<17797 17142 16698 16501 16459 16447>,
			<17785 17122 16690 16504 16460 16448>,
			<17797 17104 16685 16510 16464 16448>,
			<17819 17087 16683 16516 16468 16449>,
			<17947 17069 16685 16521 16473 16452>,
			<18166 17051 16692 16526 16478 16456>,
			<18193 17063 16702 16532 16482 16460>,
			<17874 17202 16720 16540 16487 16465>,
			<17571 17319 16746 16550 16492 16471>,
			<17514 17301 16801 16562 16498 16476>,
			<17486 17241 16871 16578 16506 16482>,
			<17428 17171 16886 16604 16518 16492>,
			<17260 17080 16869 16650 16542 16508>,
			<17084 16981 16840 16675 16558 16518>,
			<16981 16888 16765 16626 16535 16503>,
			<16901 16797 16651 16546 16491 16471>,
			<16876 16737 16600 16513 16472 16458>,
			<16875 16696 16581 16497 16465 16454>,
			<16877 16671 16570 16490 16462 16452>,
			<16878 16665 16565 16491 16463 16453>,
			<16880 16662 16563 16493 16466 16455>,
			<16882 16663 16561 16496 16469 16457>,
			<16892 16695 16561 16502 16474 16460>,
			<16904 16728 16560 16509 16479 16465>,
			<16915 16727 16556 16517 16487 16472>,
			<16925 16714 16548 16524 16497 16480>,
			<16936 16709 16543 16525 16499 16481>,
			<16952 16728 16541 16525 16498 16477>,
			<16969 16757 16540 16524 16497 16470>,
			<16981 16776 16544 16509 16489 16464>,
			<16990 16793 16556 16488 16472 16457>,
			<17000 16806 16567 16482 16465 16455>,
			<17015 16820 16577 16480 16463 16454>,
			<17028 16833 16590 16480 16462 16454>,
			<17034 16838 16607 16482 16461 16452>,
			<17036 16845 16630 16483 16459 16450>,
			<17039 16866 16653 16479 16451 16441>,
			<17044 16925 16685 16481 16448 16438>,
			<17080 17034 16729 16498 16466 16450>,
			<17074 17043 16744 16509 16471 16455>,
			<17120 17153 16799 16525 16478 16482>,
			<17197 17268 16872 16541 16500 16486>,
			<17289 17390 16922 16547 16476 16455>,
			<17656 17464 16946 16518 16460 16450>,
			<18914 17560 17015 16540 16466 16461>,
			<25385 18839 17177 16582 16487 16479>,
			<65535 25835 17615 16666 16570 16587>,
			<65535 25835 17615 16666 16570 16587>,
			<65535 25835 17615 16666 16570 16587>;
	};

	qcom,pc-temp-y5-lut {
		qcom,lut-col-legend = <(-10) 0 10 25 40 50>;
		qcom,lut-row-legend = <10000 9800 9600 9400 9200 9000>,
			<8800 8600 8400 8200 8000 7800>,
			<7600 7400 7200 7000 6800 6600>,
			<6400 6200 6000 5800 5600 5400>,
			<5200 5000 4800 4600 4400 4200>,
			<4000 3800 3600 3400 3200 3000>,
			<2800 2600 2400 2200 2000 1800>,
			<1600 1400 1200 1000 900 800>,
			<700 600 500 400 300 200>,
			<100 0>;
		qcom,lut-data = <8712 15026 15531 19379 18638 18873>,
			<9360 15119 15904 18548 17744 18608>,
			<10576 15245 16140 17660 16983 18158>,
			<11994 15378 16270 16808 16379 17659>,
			<13263 15489 16325 16083 15956 17247>,
			<14035 15551 16337 15578 15737 17058>,
			<14489 15571 16219 15286 15817 17054>,
			<14915 15584 16000 15055 16004 17066>,
			<14736 15593 15886 14708 15871 17050>,
			<12904 15602 15821 14083 15297 17011>,
			<11479 15610 15739 13661 14730 16948>,
			<12549 15578 15515 13567 14342 16593>,
			<14696 15478 15153 13535 14012 15943>,
			<15204 15296 14819 13512 13842 15430>,
			<14206 14679 14439 13405 13754 14985>,
			<13348 14198 14220 13364 13731 14634>,
			<13770 14577 14233 13448 13885 14355>,
			<14768 15494 14280 13593 14218 14131>,
			<15057 16055 14480 13868 14600 14166>,
			<14465 16396 15586 14491 15325 14740>,
			<13590 16584 16549 15259 15825 15286>,
			<12641 16563 16736 16292 15795 15530>,
			<11562 16490 16839 17335 15685 15785>,
			<11068 16445 16846 17774 15792 16147>,
			<10902 16347 16717 17964 16568 17165>,
			<10820 16160 16608 18032 17165 17899>,
			<10865 15249 16733 18059 16986 17708>,
			<11010 13133 17019 18046 16558 17319>,
			<11098 11831 17109 17862 16231 17186>,
			<11103 11232 16758 17390 15906 17069>,
			<11101 10899 16449 17128 15714 16894>,
			<11141 10966 16849 17302 16092 16557>,
			<11213 11269 17719 17578 16970 16109>,
			<11261 11523 17992 17684 17585 16020>,
			<11243 11692 17704 17734 18052 16389>,
			<11210 11822 17336 17749 18308 16850>,
			<11241 11913 17101 17071 18178 17152>,
			<11311 12019 16893 16061 17864 17432>,
			<11345 12061 16680 15765 17701 17821>,
			<11305 11977 16193 15672 17545 18525>,
			<11235 11862 15697 15633 17323 19031>,
			<11172 11812 15469 15520 16906 18864>,
			<11091 11756 15327 15452 16491 18547>,
			<11065 11698 15309 15545 17844 20219>,
			<11049 11600 15301 16184 18667 20877>,
			<11033 11430 15185 16286 15912 17920>,
			<11063 11516 14855 16092 15975 19179>,
			<11193 11505 14142 15093 16646 19341>,
			<11223 11473 13900 16259 18048 18109>,
			<11359 11461 13490 17612 18268 20127>,
			<10615 11359 12967 17171 18333 22819>,
			<9756 11135 12259 17813 18591 21884>,
			<9138 9970 11638 17415 19016 19509>,
			<8857 9145 10890 17138 18770 18664>,
			<8857 9145 10890 17138 18770 18664>,
			<8857 9145 10890 17138 18770 18664>;
	};

	qcom,pc-temp-y6-lut {
		qcom,lut-col-legend = <(-10) 0 10 25 40 50>;
		qcom,lut-row-legend = <10000 9800 9600 9400 9200 9000>,
			<8800 8600 8400 8200 8000 7800>,
			<7600 7400 7200 7000 6800 6600>,
			<6400 6200 6000 5800 5600 5400>,
			<5200 5000 4800 4600 4400 4200>,
			<4000 3800 3600 3400 3200 3000>,
			<2800 2600 2400 2200 2000 1800>,
			<1600 1400 1200 1000 900 800>,
			<700 600 500 400 300 200>,
			<100 0>;
		qcom,lut-data = <6073 5498 5176 5004 4961 4950>,
			<6141 5510 5177 5003 4960 4950>,
			<6193 5518 5177 5000 4960 4950>,
			<6230 5522 5177 4998 4960 4951>,
			<6253 5523 5177 4996 4960 4951>,
			<6260 5523 5177 4995 4960 4951>,
			<6251 5515 5172 4995 4960 4952>,
			<6228 5497 5164 4995 4961 4952>,
			<6197 5485 5158 4995 4961 4953>,
			<6135 5475 5154 4995 4962 4953>,
			<6094 5468 5151 4996 4963 4954>,
			<6144 5461 5151 4997 4963 4955>,
			<6242 5456 5151 4999 4965 4956>,
			<6258 5458 5152 5001 4966 4957>,
			<6146 5485 5157 5004 4968 4959>,
			<6048 5509 5164 5008 4970 4960>,
			<6043 5502 5178 5012 4972 4962>,
			<6042 5483 5196 5019 4976 4963>,
			<6036 5459 5200 5028 4981 4966>,
			<5988 5428 5192 5043 4990 4973>,
			<5941 5394 5180 5051 4996 4977>,
			<5931 5365 5155 5035 4986 4971>,
			<5925 5338 5120 5008 4968 4959>,
			<5926 5324 5104 4997 4962 4954>,
			<5961 5317 5098 4991 4960 4953>,
			<6016 5313 5095 4989 4959 4952>,
			<6064 5308 5096 4990 4959 4952>,
			<6116 5304 5096 4991 4960 4953>,
			<6171 5303 5097 4992 4960 4954>,
			<6230 5310 5097 4993 4962 4955>,
			<6294 5324 5098 4995 4963 4956>,
			<6365 5339 5099 4997 4966 4958>,
			<6443 5360 5100 5000 4970 4960>,
			<6526 5386 5102 5000 4972 4960>,
			<6616 5418 5104 5000 4971 4959>,
			<6710 5458 5107 5000 4971 4957>,
			<6806 5503 5112 4995 4968 4955>,
			<6905 5557 5119 4988 4963 4954>,
			<6999 5617 5128 4986 4961 4953>,
			<7087 5686 5138 4986 4961 4954>,
			<7171 5765 5150 4987 4961 4954>,
			<7248 5854 5168 4988 4961 4954>,
			<7321 5958 5194 4989 4960 4953>,
			<7398 6090 5224 4989 4958 4951>,
			<7486 6260 5268 4991 4958 4951>,
			<7619 6476 5314 5000 4964 4955>,
			<7678 6544 5327 5006 4966 4958>,
			<7839 6715 5372 5012 4970 4967>,
			<8071 6924 5436 5020 4979 4968>,
			<8446 7190 5500 5024 4971 4959>,
			<9650 7528 5576 5014 4966 4958>,
			<12380 8025 5730 5025 4969 4962>,
			<19407 9840 6021 5041 4977 4968>,
			<44210 15120 6736 5073 5003 5001>,
			<44210 15120 6736 5073 5003 5001>,
			<44210 15120 6736 5073 5003 5001>;
	};

};

qcom,4391492_BBK_ATL_PD1965_5000mAH_PMI63_ThirdSupply {
    /* 4391492_BBK_ATL_PD1965_5000mAH_PMI632_averaged_MasterSlave_Jan2th2020 */
    qcom,max-voltage-uv = <4430000>;
    qcom,fg-cc-cv-threshold-uv = <4420000>;
    qcom,fastchg-current-ma = <700>;
    qcom,batt-id-kohm = <300>;
    qcom,nom-batt-capacity-mah = <4880>;/*min value*/
    qcom,battery-beta = <3440>;
    qcom,battery-therm-kohm = <10>;
    qcom,battery-type = "vivo_PD2006F_EX_batterydata:batid(300)";
    qcom,qg-batt-profile-ver = <100>;

	qcom,fcc1-temp-lut {
		qcom,lut-col-legend = <0 10 25 40 50>;
		qcom,lut-data = <4851 4902 5094 5110 5112>;
	};

	qcom,fcc2-temp-lut {
		qcom,lut-col-legend = <(-10) 0 10 25 40 50>;
		qcom,lut-data = <4949 4949 4949 5083 5064 5048>;
	};

	qcom,pc-temp-v1-lut {
		qcom,lut-col-legend = <0 10 25 40 50>;
		qcom,lut-row-legend = <10000 9800 9600 9400 9200>,
			<9000 8800 8600 8400 8200>,
			<8000 7800 7600 7400 7200>,
			<7000 6800 6600 6400 6200>,
			<6000 5800 5600 5400 5200>,
			<5000 4800 4600 4400 4200>,
			<4000 3800 3600 3400 3200>,
			<3000 2800 2600 2400 2200>,
			<2000 1800 1600 1400 1200>,
			<1000 900 800 700 600>,
			<500 400 300 200 100>,
			<0>;
		qcom,lut-data = <44122 44171 44213 44222 44223>,
			<43932 43978 43984 43985 43990>,
			<43721 43775 43765 43768 43776>,
			<43497 43563 43547 43550 43566>,
			<43267 43342 43318 43326 43345>,
			<43026 43106 43079 43094 43115>,
			<42781 42860 42834 42856 42879>,
			<42536 42615 42582 42609 42636>,
			<42289 42370 42328 42357 42387>,
			<42048 42126 42077 42108 42141>,
			<41815 41886 41829 41861 41894>,
			<41587 41649 41587 41618 41652>,
			<41363 41420 41352 41380 41415>,
			<41145 41197 41121 41147 41184>,
			<40932 40981 40898 40922 40958>,
			<40725 40772 40681 40705 40738>,
			<40525 40569 40474 40497 40527>,
			<40336 40377 40277 40296 40324>,
			<40161 40200 40090 40106 40131>,
			<39981 40025 39924 39932 39953>,
			<39787 39835 39764 39768 39784>,
			<39585 39632 39568 39577 39592>,
			<39383 39427 39317 39338 39357>,
			<39171 39212 39093 39114 39135>,
			<38983 39005 38929 38945 38964>,
			<38852 38850 38791 38801 38816>,
			<38748 38729 38668 38675 38686>,
			<38654 38625 38559 38564 38572>,
			<38566 38531 38462 38463 38469>,
			<38487 38446 38373 38369 38373>,
			<38418 38370 38294 38284 38286>,
			<38357 38299 38223 38207 38207>,
			<38303 38237 38161 38137 38133>,
			<38255 38184 38108 38075 38067>,
			<38212 38139 38068 38026 38012>,
			<38174 38099 38031 37980 37958>,
			<38141 38068 37993 37927 37891>,
			<38103 38034 37955 37868 37813>,
			<38050 37985 37903 37799 37730>,
			<37981 37918 37815 37714 37645>,
			<37897 37837 37708 37615 37549>,
			<37784 37730 37594 37499 37432>,
			<37653 37603 37463 37364 37296>,
			<37498 37455 37301 37209 37141>,
			<37338 37296 37154 37078 37013>,
			<37200 37158 37066 37001 36941>,
			<37151 37113 37041 36979 36920>,
			<37114 37078 37025 36960 36903>,
			<37081 37051 37002 36936 36876>,
			<37044 37025 36895 36796 36712>,
			<36985 36984 36560 36449 36359>,
			<36789 36839 36087 35978 35890>,
			<36178 36416 35467 35369 35281>,
			<34544 35794 34601 34535 34451>,
			<30768 34715 33240 33236 33166>,
			<30000 30000 30000 30000 30000>;
	};

	qcom,pc-temp-v2-lut {
		qcom,lut-col-legend = <(-10) 0 10 25 40 50>;
		qcom,lut-row-legend = <10000 9800 9600 9400 9200 9000>,
			<8800 8600 8400 8200 8000 7800>,
			<7600 7400 7200 7000 6800 6600>,
			<6400 6200 6000 5800 5600 5400>,
			<5200 5000 4800 4600 4400 4200>,
			<4000 3800 3600 3400 3200 3000>,
			<2800 2600 2400 2200 2000 1800>,
			<1600 1400 1200 1000 900 800>,
			<700 600 500 400 300 200>,
			<100 0>;
		qcom,lut-data = <44220 44215 44205 44185 44155 44125>,
			<43931 43958 43967 43927 43898 43878>,
			<43660 43712 43735 43676 43648 43637>,
			<43408 43478 43509 43435 43408 43401>,
			<43179 43259 43291 43205 43179 43174>,
			<42950 43036 43068 42969 42945 42941>,
			<42710 42800 42829 42722 42699 42698>,
			<42467 42558 42582 42470 42450 42452>,
			<42225 42315 42337 42219 42202 42205>,
			<41983 42070 42092 41969 41953 41958>,
			<41746 41828 41851 41723 41709 41715>,
			<41516 41592 41612 41481 41469 41476>,
			<41292 41362 41377 41245 41234 41242>,
			<41077 41137 41147 41015 41005 41013>,
			<40873 40919 40923 40792 40782 40790>,
			<40664 40704 40705 40576 40568 40575>,
			<40428 40490 40492 40368 40362 40368>,
			<40175 40278 40285 40167 40164 40169>,
			<39924 40060 40089 39984 39982 39984>,
			<39670 39836 39911 39809 39809 39809>,
			<39428 39609 39725 39609 39616 39617>,
			<39213 39377 39488 39368 39378 39378>,
			<39015 39143 39218 39133 39143 39142>,
			<38843 38946 38999 38934 38949 38953>,
			<38691 38783 38829 38755 38777 38789>,
			<38556 38640 38683 38610 38634 38649>,
			<38429 38512 38555 38492 38517 38530>,
			<38312 38398 38443 38388 38413 38424>,
			<38209 38294 38339 38291 38316 38325>,
			<38116 38197 38242 38201 38225 38232>,
			<38038 38109 38153 38123 38145 38148>,
			<37975 38028 38071 38051 38071 38071>,
			<37924 37954 37995 37985 38003 37999>,
			<37876 37892 37926 37924 37944 37933>,
			<37833 37844 37864 37866 37888 37872>,
			<37791 37801 37808 37801 37812 37789>,
			<37741 37762 37760 37732 37704 37662>,
			<37685 37726 37719 37657 37597 37534>,
			<37619 37681 37669 37579 37510 37442>,
			<37539 37614 37601 37496 37429 37361>,
			<37445 37530 37518 37409 37340 37269>,
			<37340 37423 37421 37313 37242 37165>,
			<37220 37284 37303 37198 37126 37041>,
			<37080 37140 37172 37057 36990 36898>,
			<36927 36989 37030 36921 36869 36809>,
			<36787 36832 36894 36888 36842 36781>,
			<36737 36788 36864 36868 36824 36761>,
			<36683 36747 36832 36845 36798 36731>,
			<36617 36690 36801 36798 36746 36660>,
			<36535 36619 36755 36657 36583 36415>,
			<36428 36503 36667 36297 36201 35993>,
			<36612 36279 36482 35768 35682 35440>,
			<31827 35979 36028 35071 35003 34711>,
			<31199 31345 35389 34109 34057 33683>,
			<30435 30573 35253 32582 32699 32253>,
			<29555 29689 29886 29001 29453 29550>;
	};

	qcom,pc-temp-z1-lut {
		qcom,lut-col-legend = <0 10 25 40 50>;
		qcom,lut-row-legend = <10000 9800 9600 9400 9200>,
			<9000 8800 8600 8400 8200>,
			<8000 7800 7600 7400 7200>,
			<7000 6800 6600 6400 6200>,
			<6000 5800 5600 5400 5200>,
			<5000 4800 4600 4400 4200>,
			<4000 3800 3600 3400 3200>,
			<3000 2800 2600 2400 2200>,
			<2000 1800 1600 1400 1200>,
			<1000 900 800 700 600>,
			<500 400 300 200 100>,
			<0>;
		qcom,lut-data = <11893 11442 10970 10846 10882>,
			<11834 11360 10847 10735 10744>,
			<11795 11326 10832 10726 10741>,
			<11770 11311 10824 10723 10741>,
			<11764 11304 10822 10722 10743>,
			<11762 11304 10821 10723 10745>,
			<11759 11304 10820 10723 10746>,
			<11763 11302 10818 10725 10748>,
			<11773 11299 10817 10728 10750>,
			<11776 11295 10817 10729 10752>,
			<11772 11294 10819 10731 10754>,
			<11767 11294 10821 10734 10757>,
			<11764 11294 10823 10737 10761>,
			<11763 11295 10825 10741 10767>,
			<11763 11297 10828 10744 10771>,
			<11765 11297 10832 10748 10773>,
			<11769 11296 10836 10751 10775>,
			<11770 11296 10839 10754 10775>,
			<11770 11299 10842 10756 10775>,
			<11770 11303 10846 10758 10780>,
			<11773 11304 10851 10759 10790>,
			<11779 11306 10857 10762 10795>,
			<11784 11307 10863 10767 10797>,
			<11788 11311 10868 10772 10799>,
			<11792 11317 10872 10775 10801>,
			<11795 11322 10875 10777 10804>,
			<11798 11327 10879 10780 10806>,
			<11800 11331 10882 10783 10810>,
			<11800 11336 10886 10787 10813>,
			<11800 11339 10893 10791 10814>,
			<11802 11340 10900 10795 10815>,
			<11807 11339 10902 10797 10818>,
			<11810 11338 10904 10798 10821>,
			<11812 11340 10906 10799 10824>,
			<11814 11347 10908 10801 10825>,
			<11818 11352 10912 10803 10827>,
			<11826 11355 10915 10806 10828>,
			<11831 11359 10919 10809 10831>,
			<11830 11364 10921 10811 10832>,
			<11830 11372 10922 10811 10832>,
			<11830 11375 10922 10812 10832>,
			<11834 11366 10924 10812 10833>,
			<11838 11361 10927 10812 10835>,
			<11837 11371 10927 10812 10838>,
			<11852 11376 10929 10813 10838>,
			<11838 11375 10930 10813 10835>,
			<11836 11368 10930 10813 10836>,
			<11824 11363 10932 10813 10837>,
			<11833 11371 10934 10816 10837>,
			<11854 11366 10937 10817 10840>,
			<11852 11367 10943 10820 10843>,
			<11853 11385 10951 10826 10846>,
			<11846 11385 10955 10830 10851>,
			<11871 11392 10967 10840 10860>,
			<11871 11392 10967 10840 10860>,
			<11871 11392 10967 10840 10860>;
	};

	qcom,pc-temp-z2-lut {
		qcom,lut-col-legend = <0 10 25 40 50>;
		qcom,lut-row-legend = <10000 9800 9600 9400 9200>,
			<9000 8800 8600 8400 8200>,
			<8000 7800 7600 7400 7200>,
			<7000 6800 6600 6400 6200>,
			<6000 5800 5600 5400 5200>,
			<5000 4800 4600 4400 4200>,
			<4000 3800 3600 3400 3200>,
			<3000 2800 2600 2400 2200>,
			<2000 1800 1600 1400 1200>,
			<1000 900 800 700 600>,
			<500 400 300 200 100>,
			<0>;
		qcom,lut-data = <10766 10988 11856 11508 11567>,
			<10868 10998 11368 11382 11657>,
			<10807 11009 11384 11509 11722>,
			<10736 11021 11431 11700 11828>,
			<10721 11028 11428 11695 11837>,
			<10751 11024 11395 11547 11733>,
			<10780 11017 11380 11472 11646>,
			<10784 11018 11405 11532 11661>,
			<10783 11048 11433 11600 11714>,
			<10787 11075 11443 11592 11725>,
			<10812 11073 11454 11565 11728>,
			<10837 11065 11458 11556 11737>,
			<10841 11064 11438 11634 11783>,
			<10841 11099 11416 11723 11837>,
			<10841 11141 11407 11706 11854>,
			<10838 11157 11394 11628 11860>,
			<10833 11171 11375 11620 11861>,
			<10828 11176 11334 11752 11886>,
			<10822 11150 11305 11877 11912>,
			<10811 11104 11310 11844 11920>,
			<10771 11051 11324 11736 11933>,
			<10709 10980 11350 11668 11912>,
			<10692 10945 11422 11634 11715>,
			<10702 10959 11465 11597 11556>,
			<10711 10981 11437 11521 11615>,
			<10704 10982 11388 11430 11734>,
			<10685 10961 11368 11419 11759>,
			<10677 10947 11356 11474 11742>,
			<10689 10955 11352 11527 11730>,
			<10704 10972 11355 11551 11788>,
			<10710 10981 11364 11574 11888>,
			<10714 10987 11383 11628 11941>,
			<10715 10993 11429 11733 11975>,
			<10723 11000 11456 11792 11998>,
			<10735 11008 11439 11748 12014>,
			<10740 11012 11418 11698 12033>,
			<10748 11013 11438 11761 12101>,
			<10759 11014 11494 11931 12251>,
			<10779 11040 11554 12030 12311>,
			<10811 11105 11655 12071 12258>,
			<10837 11135 11730 12090 12202>,
			<10857 11137 11692 12054 12162>,
			<10874 11140 11627 11966 12082>,
			<10887 11162 11656 11848 12020>,
			<10993 11268 11682 11852 11966>,
			<11103 11442 11767 11824 12099>,
			<10954 11413 11598 11897 12113>,
			<10973 11371 11653 11890 11995>,
			<11220 11422 11746 12013 12175>,
			<10731 11396 12110 11712 11562>,
			<10529 11406 12009 11403 11380>,
			<10366 11206 11707 11252 11299>,
			<10437 11003 11373 11156 11215>,
			<9310 10745 11095 11098 11233>,
			<9310 10745 11095 11098 11233>,
			<9310 10745 11095 11098 11233>;
	};

	qcom,pc-temp-z3-lut {
		qcom,lut-col-legend = <0 10 25 40 50>;
		qcom,lut-row-legend = <10000 9800 9600 9400 9200>,
			<9000 8800 8600 8400 8200>,
			<8000 7800 7600 7400 7200>,
			<7000 6800 6600 6400 6200>,
			<6000 5800 5600 5400 5200>,
			<5000 4800 4600 4400 4200>,
			<4000 3800 3600 3400 3200>,
			<3000 2800 2600 2400 2200>,
			<2000 1800 1600 1400 1200>,
			<1000 900 800 700 600>,
			<500 400 300 200 100>,
			<0>;
		qcom,lut-data = <19330 19322 19309 19300 19298>,
			<19483 19424 19352 19312 19310>,
			<19556 19456 19363 19323 19311>,
			<19604 19463 19373 19331 19310>,
			<19612 19466 19372 19331 19310>,
			<19598 19466 19364 19321 19310>,
			<19584 19464 19359 19315 19310>,
			<19579 19460 19357 19314 19308>,
			<19575 19447 19357 19314 19306>,
			<19569 19436 19355 19312 19305>,
			<19554 19434 19352 19311 19305>,
			<19539 19434 19348 19310 19305>,
			<19535 19432 19336 19310 19300>,
			<19533 19423 19327 19310 19294>,
			<19533 19413 19326 19308 19293>,
			<19533 19406 19327 19302 19293>,
			<19534 19400 19327 19299 19292>,
			<19534 19398 19326 19300 19292>,
			<19534 19403 19326 19300 19291>,
			<19534 19413 19328 19299 19292>,
			<19547 19423 19330 19297 19293>,
			<19573 19438 19335 19298 19296>,
			<19587 19449 19354 19310 19306>,
			<19593 19456 19366 19320 19315>,
			<19596 19462 19363 19318 19316>,
			<19597 19464 19359 19314 19316>,
			<19596 19467 19359 19313 19316>,
			<19595 19469 19360 19315 19313>,
			<19593 19463 19361 19316 19309>,
			<19590 19454 19360 19315 19305>,
			<19586 19451 19358 19314 19301>,
			<19580 19451 19358 19313 19297>,
			<19575 19452 19358 19313 19295>,
			<19570 19450 19357 19312 19293>,
			<19565 19446 19354 19310 19293>,
			<19563 19445 19350 19308 19293>,
			<19562 19445 19346 19307 19294>,
			<19561 19445 19343 19305 19296>,
			<19555 19441 19341 19305 19297>,
			<19544 19433 19340 19306 19294>,
			<19530 19426 19339 19307 19292>,
			<19509 19419 19331 19310 19293>,
			<19495 19413 19321 19314 19296>,
			<19490 19405 19325 19314 19299>,
			<19412 19385 19326 19308 19300>,
			<19339 19357 19321 19298 19296>,
			<19327 19351 19323 19297 19291>,
			<19308 19357 19309 19294 19291>,
			<19285 19343 19303 19293 19291>,
			<19311 19319 19294 19304 19305>,
			<19312 19318 19298 19319 19307>,
			<19354 19344 19304 19318 19306>,
			<19555 19410 19323 19320 19309>,
			<19825 19452 19361 19318 19311>,
			<19825 19452 19361 19318 19311>,
			<19825 19452 19361 19318 19311>;
	};

	qcom,pc-temp-z4-lut {
		qcom,lut-col-legend = <0 10 25 40 50>;
		qcom,lut-row-legend = <10000 9800 9600 9400 9200>,
			<9000 8800 8600 8400 8200>,
			<8000 7800 7600 7400 7200>,
			<7000 6800 6600 6400 6200>,
			<6000 5800 5600 5400 5200>,
			<5000 4800 4600 4400 4200>,
			<4000 3800 3600 3400 3200>,
			<3000 2800 2600 2400 2200>,
			<2000 1800 1600 1400 1200>,
			<1000 900 800 700 600>,
			<500 400 300 200 100>,
			<0>;
		qcom,lut-data = <15335 15096 14822 14768 14748>,
			<15348 15101 14931 14798 14748>,
			<15297 15089 14901 14790 14746>,
			<15192 15013 14851 14767 14735>,
			<15114 14939 14831 14757 14727>,
			<15053 14912 14822 14753 14723>,
			<15008 14893 14813 14749 14718>,
			<14984 14880 14803 14743 14714>,
			<14966 14871 14793 14737 14710>,
			<14955 14862 14783 14731 14706>,
			<14949 14850 14774 14727 14701>,
			<14944 14836 14768 14721 14696>,
			<14935 14828 14765 14714 14694>,
			<14923 14825 14762 14707 14691>,
			<14918 14824 14754 14702 14687>,
			<14926 14825 14744 14698 14681>,
			<14938 14831 14735 14693 14675>,
			<14935 14833 14726 14684 14669>,
			<14905 14812 14720 14676 14664>,
			<14883 14787 14715 14674 14659>,
			<14902 14793 14712 14673 14654>,
			<14949 14834 14722 14677 14656>,
			<14993 14874 14792 14715 14685>,
			<15043 14905 14841 14749 14710>,
			<15077 14928 14838 14756 14712>,
			<15061 14928 14830 14760 14713>,
			<15011 14899 14820 14759 14713>,
			<14979 14871 14805 14748 14710>,
			<14966 14858 14791 14737 14707>,
			<14958 14847 14779 14729 14703>,
			<14957 14840 14770 14721 14699>,
			<14956 14835 14763 14713 14694>,
			<14956 14831 14757 14704 14689>,
			<14953 14829 14752 14699 14684>,
			<14949 14827 14749 14696 14677>,
			<14942 14824 14748 14694 14672>,
			<14932 14818 14752 14699 14676>,
			<14920 14811 14764 14717 14690>,
			<14905 14808 14769 14725 14696>,
			<14887 14806 14768 14718 14692>,
			<14871 14801 14767 14709 14686>,
			<14858 14782 14762 14699 14679>,
			<14844 14765 14753 14691 14674>,
			<14827 14758 14746 14692 14673>,
			<14879 14759 14742 14696 14671>,
			<14940 14780 14729 14692 14664>,
			<14944 14780 14711 14681 14660>,
			<14950 14758 14695 14665 14646>,
			<14962 14756 14685 14652 14636>,
			<14933 14771 14711 14652 14636>,
			<14939 14772 14711 14640 14635>,
			<14951 14774 14705 14640 14636>,
			<15017 14769 14691 14642 14641>,
			<16128 14860 14692 14654 14649>,
			<16128 14860 14692 14654 14649>,
			<16128 14860 14692 14654 14649>;
	};

	qcom,pc-temp-z5-lut {
		qcom,lut-col-legend = <0 10 25 40 50>;
		qcom,lut-row-legend = <10000 9800 9600 9400 9200>,
			<9000 8800 8600 8400 8200>,
			<8000 7800 7600 7400 7200>,
			<7000 6800 6600 6400 6200>,
			<6000 5800 5600 5400 5200>,
			<5000 4800 4600 4400 4200>,
			<4000 3800 3600 3400 3200>,
			<3000 2800 2600 2400 2200>,
			<2000 1800 1600 1400 1200>,
			<1000 900 800 700 600>,
			<500 400 300 200 100>,
			<0>;
		qcom,lut-data = <11847 12547 13468 14914 16021>,
			<14008 15287 16415 16607 18445>,
			<15649 16662 17614 18354 19404>,
			<16958 17414 18871 20504 19852>,
			<17541 17872 18896 20597 20146>,
			<17814 18160 18318 19156 20394>,
			<17933 18372 18003 18255 20500>,
			<17984 18361 18205 18360 20369>,
			<18078 17760 18456 18562 20171>,
			<18025 17214 18512 18597 20231>,
			<17519 17314 18542 18608 20630>,
			<17005 17621 18455 18645 20823>,
			<16995 17717 17422 19015 19739>,
			<17151 17287 16458 19419 18426>,
			<17236 16678 16532 19068 18329>,
			<17121 16208 16830 18121 18445>,
			<16959 15754 17069 17860 18556>,
			<16995 15600 17325 18365 19051>,
			<17461 16516 17674 18788 19605>,
			<18178 17916 18358 18800 20204>,
			<19764 18848 19238 18804 21270>,
			<21901 19660 19288 18603 21427>,
			<22331 20005 17913 17585 19589>,
			<20575 19125 16800 16605 18070>,
			<18945 17833 16585 16206 18126>,
			<19155 17792 16455 15948 18309>,
			<20102 18988 16675 16007 18435>,
			<21051 20002 17404 16687 18536>,
			<22057 20256 18212 17443 18584>,
			<22890 20431 18938 17986 18451>,
			<23150 20821 19726 18548 18249>,
			<23279 21946 20847 19289 18288>,
			<23347 22949 22561 20277 18658>,
			<23219 23262 23587 21207 19105>,
			<22994 23458 24065 22199 20330>,
			<22970 23706 24363 22927 21646>,
			<23115 24131 23999 22396 21643>,
			<23180 24445 22801 20560 20942>,
			<23052 24298 21863 19811 20441>,
			<22816 23781 21315 19931 19613>,
			<22294 23311 20703 20174 18888>,
			<20167 22628 19195 20975 19362>,
			<18814 21806 17587 22087 20404>,
			<18494 20394 17781 21660 20962>,
			<15289 18060 17720 19412 20749>,
			<12683 15619 17614 17535 19786>,
			<12437 15341 18658 17867 19132>,
			<12109 16010 17357 19440 21864>,
			<11785 15162 17072 20936 23596>,
			<12051 13701 14574 20260 30098>,
			<12053 13667 14350 26479 29693>,
			<12954 15347 14724 25466 28293>,
			<17315 19715 16686 26477 30035>,
			<10551 19007 25022 23589 27902>,
			<10551 19007 25022 23589 27902>,
			<10551 19007 25022 23589 27902>;
	};

	qcom,pc-temp-z6-lut {
		qcom,lut-col-legend = <0 10 25 40 50>;
		qcom,lut-row-legend = <10000 9800 9600 9400 9200>,
			<9000 8800 8600 8400 8200>,
			<8000 7800 7600 7400 7200>,
			<7000 6800 6600 6400 6200>,
			<6000 5800 5600 5400 5200>,
			<5000 4800 4600 4400 4200>,
			<4000 3800 3600 3400 3200>,
			<3000 2800 2600 2400 2200>,
			<2000 1800 1600 1400 1200>,
			<1000 900 800 700 600>,
			<500 400 300 200 100>,
			<0>;
		qcom,lut-data = <15066 14773 14523 14472 14466>,
			<15121 14807 14572 14473 14452>,
			<15107 14807 14563 14473 14451>,
			<15075 14772 14545 14468 14445>,
			<15041 14737 14534 14463 14442>,
			<15001 14723 14526 14456 14440>,
			<14966 14712 14519 14451 14438>,
			<14948 14701 14514 14448 14436>,
			<14935 14689 14509 14446 14433>,
			<14923 14678 14504 14444 14432>,
			<14910 14671 14499 14441 14430>,
			<14899 14664 14494 14438 14428>,
			<14891 14658 14488 14436 14425>,
			<14884 14651 14482 14434 14422>,
			<14881 14646 14478 14430 14419>,
			<14884 14644 14474 14426 14417>,
			<14889 14643 14471 14423 14415>,
			<14888 14642 14468 14419 14412>,
			<14876 14637 14466 14417 14410>,
			<14867 14632 14466 14416 14410>,
			<14883 14638 14466 14416 14410>,
			<14919 14664 14473 14418 14412>,
			<14949 14690 14515 14443 14431>,
			<14978 14710 14544 14464 14447>,
			<14996 14725 14542 14465 14449>,
			<14990 14726 14537 14465 14450>,
			<14971 14717 14533 14464 14450>,
			<14960 14707 14528 14461 14448>,
			<14955 14699 14523 14457 14445>,
			<14953 14691 14518 14453 14441>,
			<14952 14689 14514 14450 14437>,
			<14951 14688 14512 14446 14434>,
			<14950 14687 14510 14443 14430>,
			<14949 14686 14508 14440 14427>,
			<14947 14685 14505 14437 14424>,
			<14946 14684 14503 14436 14423>,
			<14946 14684 14504 14438 14425>,
			<14944 14683 14508 14445 14432>,
			<14940 14681 14509 14448 14435>,
			<14932 14678 14509 14446 14432>,
			<14923 14674 14508 14443 14428>,
			<14912 14664 14502 14441 14426>,
			<14905 14655 14493 14439 14425>,
			<14901 14650 14493 14439 14427>,
			<14886 14640 14493 14438 14427>,
			<14879 14638 14485 14431 14422>,
			<14876 14635 14478 14426 14418>,
			<14872 14629 14465 14418 14411>,
			<14868 14622 14458 14412 14406>,
			<14871 14618 14465 14418 14415>,
			<14880 14620 14469 14421 14417>,
			<14918 14638 14471 14423 14418>,
			<15072 14675 14478 14426 14423>,
			<15834 14749 14501 14432 14429>,
			<15834 14749 14501 14432 14429>,
			<15834 14749 14501 14432 14429>;
	};

	qcom,pc-temp-y1-lut {
		qcom,lut-col-legend = <(-10) 0 10 25 40 50>;
		qcom,lut-row-legend = <10000 9800 9600 9400 9200 9000>,
			<8800 8600 8400 8200 8000 7800>,
			<7600 7400 7200 7000 6800 6600>,
			<6400 6200 6000 5800 5600 5400>,
			<5200 5000 4800 4600 4400 4200>,
			<4000 3800 3600 3400 3200 3000>,
			<2800 2600 2400 2200 2000 1800>,
			<1600 1400 1200 1000 900 800>,
			<700 600 500 400 300 200>,
			<100 0>;
		qcom,lut-data = <5683 5244 5045 4729 4671 4672>,
			<5688 5251 5042 4735 4671 4674>,
			<5691 5256 5037 4739 4671 4677>,
			<5695 5259 5031 4741 4672 4679>,
			<5698 5261 5026 4741 4673 4682>,
			<5699 5262 5024 4740 4674 4684>,
			<5697 5261 5023 4738 4674 4685>,
			<5691 5258 5023 4734 4676 4686>,
			<5689 5256 5023 4733 4677 4687>,
			<5684 5253 5022 4732 4678 4689>,
			<5681 5251 5021 4732 4680 4691>,
			<5682 5251 5019 4733 4680 4693>,
			<5684 5251 5014 4735 4681 4695>,
			<5683 5251 5013 4735 4682 4697>,
			<5677 5252 5012 4735 4683 4699>,
			<5672 5253 5011 4735 4684 4700>,
			<5675 5255 5011 4736 4685 4700>,
			<5683 5257 5011 4738 4685 4701>,
			<5684 5258 5010 4741 4687 4702>,
			<5681 5256 5009 4744 4691 4704>,
			<5678 5253 5008 4747 4692 4706>,
			<5684 5256 5009 4749 4693 4707>,
			<5699 5262 5012 4750 4694 4708>,
			<5704 5265 5013 4752 4696 4709>,
			<5695 5263 5013 4754 4699 4711>,
			<5685 5261 5012 4756 4701 4712>,
			<5686 5262 5013 4759 4701 4713>,
			<5691 5263 5016 4762 4702 4713>,
			<5693 5264 5018 4764 4704 4714>,
			<5689 5264 5021 4766 4706 4715>,
			<5684 5263 5023 4769 4707 4717>,
			<5689 5265 5024 4772 4708 4718>,
			<5703 5269 5025 4775 4709 4719>,
			<5709 5271 5025 4777 4711 4719>,
			<5702 5272 5027 4778 4712 4720>,
			<5693 5273 5029 4780 4713 4722>,
			<5687 5273 5028 4782 4715 4723>,
			<5676 5271 5027 4784 4716 4725>,
			<5670 5270 5027 4785 4716 4727>,
			<5671 5269 5030 4787 4715 4729>,
			<5671 5267 5035 4786 4715 4729>,
			<5668 5267 5035 4785 4717 4727>,
			<5658 5267 5034 4788 4721 4727>,
			<5659 5266 5035 4791 4724 4730>,
			<5668 5263 5038 4791 4719 4731>,
			<5670 5268 5035 4793 4723 4731>,
			<5670 5270 5045 4795 4722 4732>,
			<5675 5273 5045 4796 4724 4735>,
			<5668 5281 5044 4797 4725 4734>,
			<5692 5280 5046 4798 4726 4733>,
			<5688 5266 5057 4802 4728 4737>,
			<5725 5301 5063 4805 4734 4738>,
			<5735 5314 5076 4819 4736 4744>,
			<5756 5338 5083 4836 4740 4749>,
			<5756 5338 5083 4836 4740 4749>,
			<5756 5338 5083 4836 4740 4749>;
	};

	qcom,pc-temp-y2-lut {
		qcom,lut-col-legend = <(-10) 0 10 25 40 50>;
		qcom,lut-row-legend = <10000 9800 9600 9400 9200 9000>,
			<8800 8600 8400 8200 8000 7800>,
			<7600 7400 7200 7000 6800 6600>,
			<6400 6200 6000 5800 5600 5400>,
			<5200 5000 4800 4600 4400 4200>,
			<4000 3800 3600 3400 3200 3000>,
			<2800 2600 2400 2200 2000 1800>,
			<1600 1400 1200 1000 900 800>,
			<700 600 500 400 300 200>,
			<100 0>;
		qcom,lut-data = <11168 11632 11870 12038 12391 12237>,
			<11145 11594 11775 12028 12352 12394>,
			<11119 11534 11696 12017 12308 12471>,
			<11093 11467 11636 12006 12260 12490>,
			<11072 11409 11597 11995 12209 12471>,
			<11057 11376 11582 11984 12157 12434>,
			<11048 11362 11611 11968 12102 12345>,
			<11042 11351 11661 11947 12044 12228>,
			<11041 11349 11669 11931 11977 12151>,
			<11042 11349 11636 11917 11893 12079>,
			<11045 11347 11602 11912 11860 12040>,
			<11050 11328 11582 11912 11926 12034>,
			<11061 11298 11562 11906 12000 12036>,
			<11076 11287 11558 11874 11993 12060>,
			<11110 11287 11561 11814 11954 12155>,
			<11140 11291 11567 11796 11939 12240>,
			<11150 11326 11581 11865 12007 12319>,
			<11157 11392 11608 11948 12087 12380>,
			<11171 11412 11631 11999 12098 12336>,
			<11211 11403 11654 12049 12102 12181>,
			<11251 11395 11670 12072 12132 12119>,
			<11119 11414 11672 12081 12198 12271>,
			<10775 11474 11672 12089 12270 12473>,
			<10694 11541 11682 12097 12358 12580>,
			<11096 11640 11794 12104 12486 12658>,
			<11486 11723 11904 12138 12545 12700>,
			<11342 11744 11904 12278 12556 12703>,
			<10897 11755 11883 12375 12569 12717>,
			<10736 11768 11875 12353 12618 12837>,
			<11128 11788 11900 12302 12713 13040>,
			<11548 11805 11926 12275 12797 13113>,
			<11315 11809 11932 12287 12868 13096>,
			<10485 11809 11944 12305 12942 13080>,
			<10030 11806 11949 12310 13086 13143>,
			<9944 11783 11952 12309 13242 13276>,
			<9890 11744 11950 12333 13214 13298>,
			<9838 11680 11926 12406 12944 13109>,
			<9792 11556 11875 12443 12773 12934>,
			<9756 11446 11844 12371 12766 12901>,
			<9726 11384 11843 12286 12763 12879>,
			<9703 11316 11843 12274 12752 12876>,
			<9690 11074 11811 12286 12711 12884>,
			<9681 10543 11720 12380 12630 12803>,
			<9674 10447 11635 12460 12481 12474>,
			<9668 10457 11537 12186 12447 12691>,
			<9664 9926 11368 12275 12351 12377>,
			<9662 9835 11343 12249 12342 12370>,
			<9660 9745 11274 12169 12244 12231>,
			<9658 9708 11173 12028 12062 11969>,
			<9663 9676 11001 11900 12003 12072>,
			<9783 9662 10777 11774 11941 11913>,
			<9665 9670 10411 11581 11797 11858>,
			<9669 9701 9711 11316 11659 11688>,
			<9656 9683 59452 10954 11602 11563>,
			<9656 9683 59452 10954 11602 11563>,
			<9656 9683 59452 10954 11602 11563>;
	};

	qcom,pc-temp-y3-lut {
		qcom,lut-col-legend = <(-10) 0 10 25 40 50>;
		qcom,lut-row-legend = <10000 9800 9600 9400 9200 9000>,
			<8800 8600 8400 8200 8000 7800>,
			<7600 7400 7200 7000 6800 6600>,
			<6400 6200 6000 5800 5600 5400>,
			<5200 5000 4800 4600 4400 4200>,
			<4000 3800 3600 3400 3200 3000>,
			<2800 2600 2400 2200 2000 1800>,
			<1600 1400 1200 1000 900 800>,
			<700 600 500 400 300 200>,
			<100 0>;
		qcom,lut-data = <13352 13309 13296 13271 13265 13270>,
			<13362 13312 13298 13271 13266 13269>,
			<13372 13315 13300 13271 13267 13268>,
			<13381 13318 13302 13272 13269 13268>,
			<13388 13320 13303 13272 13269 13267>,
			<13392 13322 13304 13273 13270 13267>,
			<13392 13324 13301 13273 13270 13267>,
			<13391 13326 13296 13273 13270 13268>,
			<13391 13326 13295 13273 13270 13268>,
			<13390 13324 13297 13273 13271 13269>,
			<13390 13322 13298 13273 13271 13270>,
			<13393 13325 13298 13274 13271 13270>,
			<13397 13331 13296 13275 13271 13270>,
			<13400 13336 13296 13275 13271 13270>,
			<13403 13338 13296 13277 13270 13270>,
			<13405 13340 13297 13278 13270 13269>,
			<13401 13340 13299 13278 13270 13269>,
			<13391 13340 13302 13279 13270 13269>,
			<13383 13339 13305 13281 13272 13269>,
			<13377 13336 13309 13285 13275 13269>,
			<13371 13332 13312 13286 13276 13269>,
			<13357 13329 13310 13284 13273 13269>,
			<13335 13325 13304 13280 13270 13268>,
			<13325 13321 13299 13277 13269 13268>,
			<13326 13313 13294 13273 13268 13267>,
			<13327 13305 13291 13271 13268 13267>,
			<13316 13304 13291 13271 13268 13267>,
			<13297 13303 13294 13272 13268 13267>,
			<13290 13303 13295 13272 13268 13267>,
			<13293 13302 13294 13272 13268 13267>,
			<13298 13302 13294 13273 13268 13267>,
			<13299 13301 13293 13275 13267 13266>,
			<13299 13300 13291 13276 13267 13265>,
			<13300 13300 13290 13276 13268 13266>,
			<13304 13299 13289 13275 13269 13266>,
			<13311 13299 13288 13275 13269 13266>,
			<13318 13303 13288 13273 13268 13266>,
			<13327 13312 13289 13272 13267 13266>,
			<13337 13317 13290 13272 13267 13266>,
			<13351 13318 13288 13273 13267 13266>,
			<13370 13319 13287 13272 13267 13267>,
			<13396 13317 13287 13271 13268 13268>,
			<13436 13310 13290 13272 13269 13269>,
			<13493 13315 13294 13274 13270 13268>,
			<13585 13328 13300 13273 13268 13267>,
			<13756 13333 13301 13272 13269 13268>,
			<13881 13340 13300 13274 13271 13270>,
			<14121 13364 13300 13279 13272 13271>,
			<14599 13421 13310 13282 13273 13271>,
			<15934 13546 13319 13283 13274 13271>,
			<16847 14015 13330 13283 13274 13271>,
			<13836 15824 13366 13288 13276 13272>,
			<15900 13441 13560 13293 13276 13272>,
			<22724 14045 15418 13312 13277 13274>,
			<22724 14045 15418 13312 13277 13274>,
			<22724 14045 15418 13312 13277 13274>;
	};

	qcom,pc-temp-y4-lut {
		qcom,lut-col-legend = <(-10) 0 10 25 40 50>;
		qcom,lut-row-legend = <10000 9800 9600 9400 9200 9000>,
			<8800 8600 8400 8200 8000 7800>,
			<7600 7400 7200 7000 6800 6600>,
			<6400 6200 6000 5800 5600 5400>,
			<5200 5000 4800 4600 4400 4200>,
			<4000 3800 3600 3400 3200 3000>,
			<2800 2600 2400 2200 2000 1800>,
			<1600 1400 1200 1000 900 800>,
			<700 600 500 400 300 200>,
			<100 0>;
		qcom,lut-data = <16752 16612 16541 16481 16457 16439>,
			<16769 16624 16540 16477 16453 16438>,
			<16790 16633 16539 16475 16449 16438>,
			<16810 16640 16538 16474 16446 16437>,
			<16827 16643 16538 16474 16444 16437>,
			<16834 16644 16538 16474 16443 16437>,
			<16831 16642 16542 16476 16444 16437>,
			<16827 16637 16549 16478 16445 16438>,
			<16826 16636 16552 16481 16447 16438>,
			<16828 16643 16553 16486 16449 16439>,
			<16832 16651 16555 16491 16452 16439>,
			<16844 16656 16561 16495 16455 16442>,
			<16869 16661 16572 16500 16458 16445>,
			<16906 16670 16582 16505 16463 16449>,
			<16980 16690 16592 16512 16469 16453>,
			<17033 16718 16605 16520 16476 16458>,
			<17031 16763 16622 16528 16482 16463>,
			<17022 16820 16643 16539 16489 16468>,
			<17000 16835 16671 16557 16499 16476>,
			<16890 16817 16721 16579 16510 16487>,
			<16786 16786 16758 16584 16514 16491>,
			<16762 16725 16715 16567 16504 16479>,
			<16752 16631 16604 16542 16490 16463>,
			<16748 16590 16545 16513 16474 16454>,
			<16718 16580 16524 16481 16457 16446>,
			<16690 16574 16512 16473 16453 16444>,
			<16698 16571 16506 16472 16453 16444>,
			<16724 16568 16502 16472 16453 16445>,
			<16733 16567 16501 16475 16454 16446>,
			<16711 16565 16503 16481 16459 16449>,
			<16688 16564 16506 16488 16464 16453>,
			<16691 16562 16510 16497 16471 16459>,
			<16708 16557 16516 16505 16479 16466>,
			<16725 16556 16519 16511 16487 16471>,
			<16738 16560 16518 16516 16494 16475>,
			<16750 16567 16517 16512 16492 16474>,
			<16764 16572 16519 16493 16472 16460>,
			<16780 16580 16522 16478 16457 16447>,
			<16793 16588 16524 16470 16454 16445>,
			<16805 16595 16520 16466 16452 16445>,
			<16815 16603 16515 16467 16450 16443>,
			<16820 16621 16516 16472 16447 16439>,
			<16824 16654 16524 16476 16446 16436>,
			<16830 16667 16535 16475 16445 16435>,
			<16843 16681 16549 16465 16441 16434>,
			<16864 16719 16555 16482 16453 16441>,
			<16882 16729 16557 16493 16454 16442>,
			<16928 16784 16575 16498 16456 16449>,
			<17020 16819 16605 16502 16466 16465>,
			<17209 16912 16645 16498 16460 16443>,
			<17202 17104 16699 16492 16449 16448>,
			<26307 17838 16779 16509 16459 16457>,
			<18958 24767 17000 16555 16472 16473>,
			<29947 17280 18072 16686 16512 16535>,
			<29947 17280 18072 16686 16512 16535>,
			<29947 17280 18072 16686 16512 16535>;
	};

	qcom,pc-temp-y5-lut {
		qcom,lut-col-legend = <(-10) 0 10 25 40 50>;
		qcom,lut-row-legend = <10000 9800 9600 9400 9200 9000>,
			<8800 8600 8400 8200 8000 7800>,
			<7600 7400 7200 7000 6800 6600>,
			<6400 6200 6000 5800 5600 5400>,
			<5200 5000 4800 4600 4400 4200>,
			<4000 3800 3600 3400 3200 3000>,
			<2800 2600 2400 2200 2000 1800>,
			<1600 1400 1200 1000 900 800>,
			<700 600 500 400 300 200>,
			<100 0>;
		qcom,lut-data = <12530 13737 15689 15092 14215 24642>,
			<13440 13909 16244 15024 15963 23804>,
			<14262 14053 16523 14887 17252 22425>,
			<14933 14170 16585 14712 18115 20910>,
			<15389 14259 16487 14530 18585 19663>,
			<15566 14321 16288 14375 18693 19089>,
			<15403 14346 15529 14211 18238 18990>,
			<15092 14322 14401 14021 17531 18928>,
			<14890 14198 14017 13812 17127 18839>,
			<14490 13743 14011 13555 16748 18731>,
			<14195 13412 14034 13372 16374 18562>,
			<14220 13593 13827 13412 16004 18104>,
			<14309 13949 13460 13536 15608 17453>,
			<14339 14037 13313 13563 15120 16852>,
			<14389 13942 13125 13555 14542 16228>,
			<14489 13861 13017 13491 14174 15688>,
			<14980 13939 13113 13409 13953 15206>,
			<15872 14187 13271 13369 13825 14830>,
			<16197 14576 13566 13532 14068 14632>,
			<16244 15558 14512 14016 14816 14492>,
			<16265 16495 15665 14685 15236 14478>,
			<15635 16900 16688 16087 15355 15297>,
			<14077 17214 17670 17092 15495 16496>,
			<13349 17213 17896 16752 16199 17628>,
			<13356 15937 16977 16044 17612 19056>,
			<13311 14635 16069 15894 18138 19538>,
			<12675 14490 16386 15891 18068 19388>,
			<11655 14486 17429 15873 17940 19150>,
			<11285 14477 18008 15899 17627 18927>,
			<11478 14446 18034 15962 16996 18658>,
			<11685 14425 17954 16246 16626 18206>,
			<11639 14430 17697 17311 16422 17023>,
			<11451 14435 16953 18041 16316 16092>,
			<11367 14432 16610 18176 16891 16338>,
			<11422 14303 16439 18249 17974 17060>,
			<11504 14198 16247 18135 18161 17601>,
			<11557 14707 16338 17646 17720 17983>,
			<11600 16199 16686 17372 17442 18293>,
			<11631 16928 16849 17394 17667 18523>,
			<11638 16605 16242 17424 18040 18785>,
			<11627 15990 15408 17026 18195 19582>,
			<11609 14986 15224 15935 18160 22306>,
			<11578 13322 15469 15716 18728 22905>,
			<11532 13212 15984 16337 19322 21854>,
			<11455 13515 16797 17144 19169 21321>,
			<11329 12098 16235 15241 16777 18846>,
			<11247 11753 15906 14809 17430 20383>,
			<11314 11723 15028 15982 17704 20699>,
			<11299 11807 15623 16544 17754 20350>,
			<23426 11676 15376 16739 19016 22678>,
			<65535 11395 14401 17489 21732 24913>,
			<12116 10872 14152 18567 22457 22970>,
			<9666 9519 11812 17225 19887 19828>,
			<8969 11371 10628 16514 18822 18749>,
			<8969 11371 10628 16514 18822 18749>,
			<8969 11371 10628 16514 18822 18749>;
	};

	qcom,pc-temp-y6-lut {
		qcom,lut-col-legend = <(-10) 0 10 25 40 50>;
		qcom,lut-row-legend = <10000 9800 9600 9400 9200 9000>,
			<8800 8600 8400 8200 8000 7800>,
			<7600 7400 7200 7000 6800 6600>,
			<6400 6200 6000 5800 5600 5400>,
			<5200 5000 4800 4600 4400 4200>,
			<4000 3800 3600 3400 3200 3000>,
			<2800 2600 2400 2200 2000 1800>,
			<1600 1400 1200 1000 900 800>,
			<700 600 500 400 300 200>,
			<100 0>;
		qcom,lut-data = <5438 5170 5060 4970 4951 4948>,
			<5442 5170 5061 4969 4951 4948>,
			<5442 5170 5061 4969 4951 4948>,
			<5440 5168 5060 4969 4951 4948>,
			<5435 5166 5059 4969 4951 4948>,
			<5429 5164 5057 4969 4951 4948>,
			<5420 5161 5054 4970 4951 4949>,
			<5410 5157 5051 4971 4952 4949>,
			<5402 5154 5051 4972 4953 4950>,
			<5395 5151 5051 4973 4954 4951>,
			<5392 5150 5051 4974 4955 4952>,
			<5394 5151 5052 4976 4956 4953>,
			<5399 5155 5053 4978 4958 4954>,
			<5408 5160 5054 4980 4959 4955>,
			<5427 5166 5057 4983 4960 4956>,
			<5442 5173 5061 4986 4962 4958>,
			<5439 5186 5066 4989 4964 4959>,
			<5430 5201 5074 4993 4966 4961>,
			<5416 5205 5084 4999 4971 4963>,
			<5384 5198 5101 5009 4976 4967>,
			<5351 5187 5113 5011 4978 4968>,
			<5332 5167 5099 5004 4973 4964>,
			<5317 5139 5064 4995 4967 4959>,
			<5310 5124 5043 4984 4961 4956>,
			<5307 5116 5034 4972 4956 4953>,
			<5305 5112 5029 4970 4954 4952>,
			<5305 5111 5029 4970 4954 4952>,
			<5304 5112 5030 4970 4955 4953>,
			<5304 5112 5031 4971 4955 4953>,
			<5307 5114 5032 4973 4956 4954>,
			<5311 5115 5033 4976 4958 4955>,
			<5317 5116 5034 4980 4960 4957>,
			<5327 5117 5036 4984 4962 4959>,
			<5338 5118 5036 4986 4966 4960>,
			<5352 5121 5036 4987 4969 4962>,
			<5368 5126 5037 4986 4968 4962>,
			<5387 5132 5038 4980 4961 4957>,
			<5409 5142 5040 4975 4956 4954>,
			<5435 5152 5042 4973 4956 4953>,
			<5468 5160 5041 4972 4955 4954>,
			<5508 5168 5039 4972 4955 4954>,
			<5555 5179 5040 4973 4955 4953>,
			<5611 5193 5046 4975 4955 4953>,
			<5682 5216 5055 4976 4956 4953>,
			<5781 5251 5065 4973 4953 4952>,
			<5936 5291 5071 4978 4957 4954>,
			<6045 5311 5072 4982 4959 4956>,
			<6242 5373 5081 4988 4961 4959>,
			<6619 5468 5101 4992 4965 4964>,
			<7483 5649 5126 4991 4964 4958>,
			<7985 6095 5165 4990 4961 4960>,
			<8672 7388 5257 5001 4965 4963>,
			<8091 7727 5578 5020 4970 4968>,
			<16082 6048 7127 5082 4983 4988>,
			<16082 6048 7127 5082 4983 4988>,
			<16082 6048 7127 5082 4983 4988>;
	};

};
